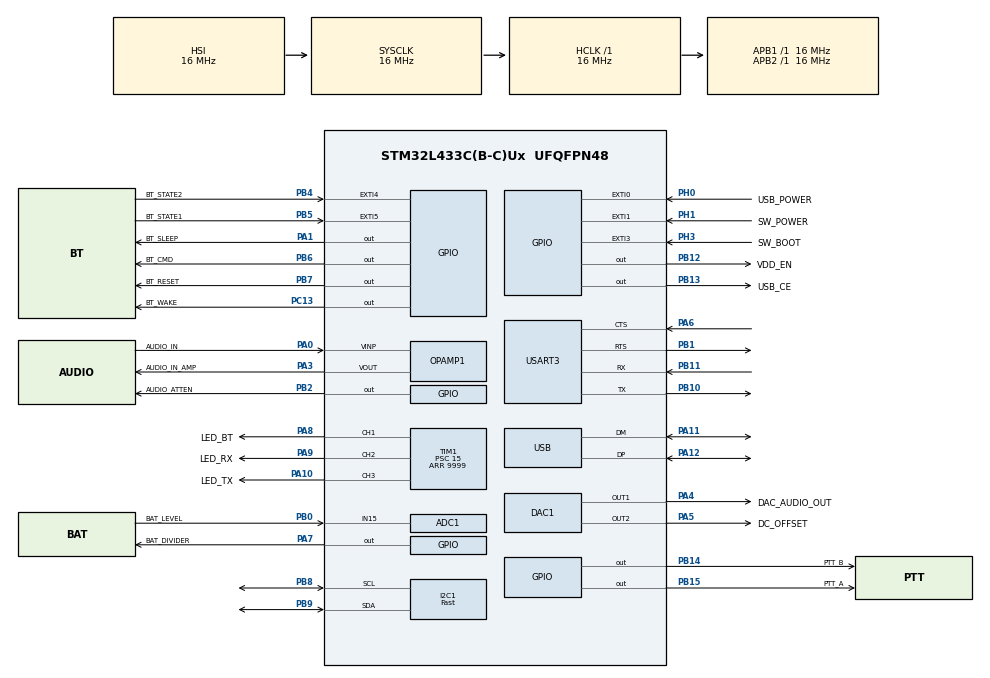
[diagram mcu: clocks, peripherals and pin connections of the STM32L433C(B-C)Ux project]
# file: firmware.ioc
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ADC1.Channel-0\#ChannelRegularConversion=ADC_CHANNEL_8
ADC1.DMAContinuousRequests=ENABLE
ADC1.EOCSelection=ADC_EOC_SEQ_CONV
ADC1.EnableAnalogWatchDog1=false
ADC1.EnableAnalogWatchDog2=false
ADC1.EnableInjectedConversion=ENABLE
ADC1.ExternalTrigConv=ADC_EXTERNALTRIG_T6_TRGO
ADC1.InjNumberOfConversion=0
ADC1.NbrOfConversion=1
ADC1.NbrOfConversionFlag=1
ADC1.OffsetNumber-0\#ChannelRegularConversion=ADC_OFFSET_NONE
ADC1.Overrun=ADC_OVR_DATA_OVERWRITTEN
ADC1.OversamplingMode=ENABLE
ADC1.OversamplingStopReset=ADC_REGOVERSAMPLING_RESUMED_MODE
ADC1.Rank-0\#ChannelRegularConversion=1
ADC1.Ratio=ADC_OVERSAMPLING_RATIO_16
ADC1.RightBitShift=ADC_RIGHTBITSHIFT_2
ADC1.SamplingTime-0\#ChannelRegularConversion=ADC_SAMPLETIME_24CYCLES_5
ADC1.master=1
CRC.CRCLength=CRC_POLYLENGTH_16B
CRC.DefaultInitValueUse=DEFAULT_INIT_VALUE_DISABLE
CRC.DefaultPolynomialUse=DEFAULT_POLYNOMIAL_DISABLE
CRC.GeneratingPolynomial=X12+X5+X0
CRC.InitValue=0xFFFF
CRC.InputDataInversionMode=CRC_INPUTDATA_INVERSION_BYTE
DAC1.DAC_Channel-DAC_OUT2_ExtAndInt=DAC_CHANNEL_2
DAC1.DAC_Trigger-DAC_OUT1_ExtAndInt=DAC_TRIGGER_T7_TRGO
DAC1.DAC_Trigger-DAC_OUT2_ExtAndInt=DAC_TRIGGER_NONE
Dma.ADC1.0.Direction=DMA_PERIPH_TO_MEMORY
Dma.ADC1.0.Instance=DMA1_Channel1
Dma.ADC1.0.MemDataAlignment=DMA_MDATAALIGN_HALFWORD
Dma.ADC1.0.MemInc=DMA_MINC_ENABLE
Dma.ADC1.0.Mode=DMA_CIRCULAR
Dma.ADC1.0.PeriphDataAlignment=DMA_PDATAALIGN_HALFWORD
Dma.ADC1.0.PeriphInc=DMA_PINC_DISABLE
Dma.ADC1.0.Priority=DMA_PRIORITY_LOW
Dma.DAC_CH1.1.Direction=DMA_MEMORY_TO_PERIPH
Dma.DAC_CH1.1.Instance=DMA2_Channel4
Dma.DAC_CH1.1.MemDataAlignment=DMA_MDATAALIGN_HALFWORD
Dma.DAC_CH1.1.MemInc=DMA_MINC_ENABLE
Dma.DAC_CH1.1.Mode=DMA_CIRCULAR
Dma.DAC_CH1.1.PeriphDataAlignment=DMA_PDATAALIGN_HALFWORD
Dma.DAC_CH1.1.PeriphInc=DMA_PINC_DISABLE
Dma.DAC_CH1.1.Priority=DMA_PRIORITY_LOW
Dma.I2C1_RX.5.Direction=DMA_PERIPH_TO_MEMORY
Dma.I2C1_RX.5.Instance=DMA1_Channel7
Dma.I2C1_RX.5.MemDataAlignment=DMA_MDATAALIGN_BYTE
Dma.I2C1_RX.5.MemInc=DMA_MINC_ENABLE
Dma.I2C1_RX.5.Mode=DMA_NORMAL
Dma.I2C1_RX.5.PeriphDataAlignment=DMA_PDATAALIGN_BYTE
Dma.I2C1_RX.5.PeriphInc=DMA_PINC_DISABLE
Dma.I2C1_RX.5.Priority=DMA_PRIORITY_LOW
Dma.I2C1_TX.4.Direction=DMA_MEMORY_TO_PERIPH
Dma.I2C1_TX.4.Instance=DMA1_Channel6
Dma.I2C1_TX.4.MemDataAlignment=DMA_MDATAALIGN_BYTE
Dma.I2C1_TX.4.MemInc=DMA_MINC_ENABLE
Dma.I2C1_TX.4.Mode=DMA_NORMAL
Dma.I2C1_TX.4.PeriphDataAlignment=DMA_PDATAALIGN_BYTE
Dma.I2C1_TX.4.PeriphInc=DMA_PINC_DISABLE
Dma.I2C1_TX.4.Priority=DMA_PRIORITY_LOW
Dma.Request0=ADC1
Dma.Request1=DAC_CH1
Dma.Request2=USART3_TX
Dma.Request3=USART3_RX
Dma.Request4=I2C1_TX
Dma.Request5=I2C1_RX
Dma.USART3_RX.3.Direction=DMA_PERIPH_TO_MEMORY
Dma.USART3_RX.3.Instance=DMA1_Channel3
Dma.USART3_RX.3.MemDataAlignment=DMA_MDATAALIGN_BYTE
Dma.USART3_RX.3.MemInc=DMA_MINC_ENABLE
Dma.USART3_RX.3.Mode=DMA_CIRCULAR
Dma.USART3_RX.3.PeriphDataAlignment=DMA_PDATAALIGN_BYTE
Dma.USART3_RX.3.PeriphInc=DMA_PINC_DISABLE
Dma.USART3_RX.3.Priority=DMA_PRIORITY_LOW
Dma.USART3_TX.2.Direction=DMA_MEMORY_TO_PERIPH
Dma.USART3_TX.2.Instance=DMA1_Channel2
Dma.USART3_TX.2.MemDataAlignment=DMA_MDATAALIGN_BYTE
Dma.USART3_TX.2.MemInc=DMA_MINC_ENABLE
Dma.USART3_TX.2.Mode=DMA_NORMAL
Dma.USART3_TX.2.PeriphDataAlignment=DMA_PDATAALIGN_BYTE
Dma.USART3_TX.2.PeriphInc=DMA_PINC_DISABLE
Dma.USART3_TX.2.Priority=DMA_PRIORITY_LOW
FREERTOS.HEAP_NUMBER=3
FREERTOS.MEMORY_ALLOCATION=2
FREERTOS.Queues01=ioEventQueue,16,uint32_t,0,Static,ioEventQueueBuffer,ioEventQueueControlBlock;audioInputQueue,8,uint8_t,0,Static,audioInputQueueBuffer,audioInputQueueControlBlock;hdlcInputQueue,3,uint32_t,0,Static,hdlcInputQueueBuffer,hdlcInputQueueControlBlock;hdlcOutputQueue,3,uint32_t,0,Static,hdlcOutputQueueBuffer,hdlcOutputQueueControlBlock;dacOutputQueue,128,uint8_t,0,Static,dacOutputQueueBuffer,dacOutputQueueControlBlock;adcInputQueue,3,uint32_t,0,Static,adcInputQueueBuffer,adcInputQueueControlBlock
FREERTOS.Tasks01=ioEventTask,-2,384,startIOEventTask,As weak,NULL,Static,ioEventTaskBuffer,ioEventTaskControlBlock;audioInputTask,1,512,startAudioInputTask,As external,NULL,Static,audioInputTaskBuffer,audioInputTaskControlBlock;modulatorTask,1,384,startModulatorTask,As external,NULL,Static,modulatorTaskBuffer,modulatorTaskControlBlock
FREERTOS.Timers01=usbShutdownTimer,shutdown,osTimerOnce,Default,NULL,Static,usbShutdownTimerControlBlock;powerOffTimer,powerOffTimerCallback,osTimerOnce,Default,NULL,Static,powerOffTimerControlBlock
FREERTOS.configCHECK_FOR_STACK_OVERFLOW=1
FREERTOS.configENABLE_BACKWARD_COMPATIBILITY=0
FREERTOS.configENABLE_FPU=1
FREERTOS.configTOTAL_HEAP_SIZE=2048
FREERTOS.configUSE_APPLICATION_TASK_TAG=0
FREERTOS.configUSE_MALLOC_FAILED_HOOK=1
FREERTOS.configUSE_NEWLIB_REENTRANT=1
FREERTOS.configUSE_TICKLESS_IDLE=0
FREERTOS.configUSE_TIMERS=1
I2C1.I2C_Speed_Mode=I2C_Fast
I2C1.Timing=0x00300617
IWDG.Prescaler=IWDG_PRESCALER_64
Mcu.Family=STM32L4
Mcu.Name=STM32L433C(B-C)Ux
Mcu.Package=UFQFPN48
Mcu.UserConstants=EEPROM_ADDRESS,0xA0;EEPROM_CAPACITY,4096;EEPROM_PAGE_SIZE,32;EEPROM_WRITE_TIME,5
NVIC.ADC1_IRQn=true\:5\:0\:false\:false\:true\:true\:true\:false\:false
NVIC.DMA1_Channel1_IRQn=true\:5\:0\:false\:false\:true\:true\:false\:true\:true
NVIC.DMA1_Channel2_IRQn=true\:5\:0\:false\:false\:true\:true\:false\:true\:true
NVIC.DMA1_Channel3_IRQn=true\:5\:0\:false\:false\:true\:true\:false\:true\:true
NVIC.DMA1_Channel6_IRQn=true\:5\:0\:false\:false\:true\:true\:false\:true\:true
NVIC.DMA1_Channel7_IRQn=true\:5\:0\:false\:false\:true\:true\:false\:true\:true
NVIC.DMA2_Channel4_IRQn=true\:5\:0\:false\:false\:true\:true\:false\:true\:true
NVIC.EXTI0_IRQn=true\:5\:0\:true\:false\:true\:true\:true\:true\:false
NVIC.EXTI1_IRQn=true\:5\:0\:true\:false\:true\:true\:true\:true\:false
NVIC.EXTI3_IRQn=true\:5\:0\:true\:false\:true\:true\:true\:true\:false
NVIC.EXTI4_IRQn=true\:5\:0\:false\:false\:true\:true\:true\:true\:false
NVIC.EXTI9_5_IRQn=true\:5\:0\:false\:false\:true\:true\:true\:true\:false
NVIC.PriorityGroup=NVIC_PRIORITYGROUP_4
NVIC.TIM1_UP_TIM16_IRQn=true\:5\:0\:false\:false\:true\:true\:true\:true\:true
NVIC.TIM2_IRQn=true\:0\:0\:false\:false\:true\:false\:false\:true\:true
NVIC.TimeBase=TIM2_IRQn
NVIC.TimeBaseIP=TIM2
NVIC.USART3_IRQn=true\:5\:0\:false\:false\:true\:true\:true\:true\:true
NVIC.USB_IRQn=true\:5\:0\:false\:false\:true\:true\:false\:true\:true
OPAMP1.PowerSupplyRange=OPAMP_POWERSUPPLY_HIGH
PA0.GPIO_Label=AUDIO_IN
PA0.Mode=PGA Not Connected
PA0.Signal=OPAMP1_VINP
PA1.GPIO_Label=BT_SLEEP
PA1.GPIO_ModeDefaultOutputPP=GPIO_MODE_OUTPUT_PP
PA1.PinState=GPIO_PIN_SET
PA1.Signal=GPIO_Output
PA10.GPIO_Label=LED_TX
PA10.GPIO_ModeDefaultOutputPP=GPIO_MODE_OUTPUT_OD
PA10.GPIO_ModeDefaultPP=GPIO_MODE_AF_OD
PA10.PinState=GPIO_PIN_SET
PA10.Signal=SharedStack_PA10
PA10.Stacked=true
PA11.Mode=Device
PA11.Signal=USB_DM
PA12.Mode=Device
PA12.Signal=USB_DP
PA13\ (JTMS-SWDIO).Mode=Trace_Asynchronous_SW
PA13\ (JTMS-SWDIO).Signal=SYS_JTMS-SWDIO
PA14\ (JTCK-SWCLK).Mode=Trace_Asynchronous_SW
PA14\ (JTCK-SWCLK).Signal=SYS_JTCK-SWCLK
PA2.Mode=Clock-out-LSCO
PA2.Signal=RCC_LSCO
PA3.GPIO_Label=AUDIO_IN_AMP
PA3.Mode=PGA Not Connected
PA3.Signal=OPAMP1_VOUT
PA4.GPIO_Label=DAC_AUDIO_OUT
PA4.Signal=COMP_DAC11_group
PA5.GPIO_Label=DC_OFFSET
PA5.Signal=COMP_DAC12_group
PA6.Mode=CTS_RTS
PA6.Signal=USART3_CTS
PA7.GPIO_Label=BAT_DIVIDER
PA7.GPIO_ModeDefaultOutputPP=GPIO_MODE_OUTPUT_OD
PA7.PinState=GPIO_PIN_SET
PA7.Signal=GPIO_Output
PA8.GPIO_Label=LED_BT
PA8.GPIO_ModeDefaultOutputPP=GPIO_MODE_OUTPUT_OD
PA8.GPIO_ModeDefaultPP=GPIO_MODE_AF_OD
PA8.PinState=GPIO_PIN_SET
PA8.Signal=S_TIM1_CH1
PA8.Stacked=true
PA9.GPIO_Label=LED_RX
PA9.GPIO_ModeDefaultOutputPP=GPIO_MODE_OUTPUT_OD
PA9.GPIO_ModeDefaultPP=GPIO_MODE_AF_OD
PA9.PinState=GPIO_PIN_SET
PA9.Signal=SharedStack_PA9
PA9.Stacked=true
PB0.GPIO_Label=BAT_LEVEL
PB0.Signal=ADCx_IN15
PB1.Mode=CTS_RTS
PB1.Signal=USART3_RTS
PB10.Mode=Asynchronous
PB10.Signal=USART3_TX
PB11.GPIO_PuPd=GPIO_NOPULL
PB11.Mode=Asynchronous
PB11.Signal=USART3_RX
PB12.GPIO_Label=VDD_EN
PB12.PinState=GPIO_PIN_SET
PB12.Signal=GPIO_Output
PB13.GPIO_Label=USB_CE
PB13.GPIO_ModeDefaultOutputPP=GPIO_MODE_OUTPUT_OD
PB13.PinState=GPIO_PIN_SET
PB13.Signal=GPIO_Output
PB14.GPIO_Label=PTT_B
PB14.Signal=GPIO_Output
PB15.GPIO_Label=PTT_A
PB15.Signal=GPIO_Output
PB2.GPIO_Label=AUDIO_ATTEN
PB2.GPIO_ModeDefaultOutputPP=GPIO_MODE_OUTPUT_OD
PB2.PinState=GPIO_PIN_SET
PB2.Signal=GPIO_Output
PB3\ (JTDO-TRACESWO).Mode=Trace_Asynchronous_SW
PB3\ (JTDO-TRACESWO).Signal=SYS_JTDO-SWO
PB4\ (NJTRST).GPIO_Label=BT_STATE2
PB4\ (NJTRST).GPIO_ModeDefaultEXTI=GPIO_MODE_IT_RISING_FALLING
PB4\ (NJTRST).Signal=GPXTI4
PB5.GPIO_Label=BT_STATE1
PB5.GPIO_ModeDefaultEXTI=GPIO_MODE_IT_RISING_FALLING
PB5.Signal=GPXTI5
PB6.GPIO_Label=BT_CMD
PB6.GPIO_ModeDefaultOutputPP=GPIO_MODE_OUTPUT_OD
PB6.PinState=GPIO_PIN_SET
PB6.Signal=GPIO_Output
PB7.GPIO_Label=BT_RESET
PB7.GPIO_ModeDefaultOutputPP=GPIO_MODE_OUTPUT_OD
PB7.PinState=GPIO_PIN_SET
PB7.Signal=GPIO_Output
PB8.GPIO_Pu=GPIO_NOPULL
PB8.Mode=I2C
PB8.Signal=I2C1_SCL
PB9.GPIO_Pu=GPIO_NOPULL
PB9.Mode=I2C
PB9.Signal=I2C1_SDA
PC13.GPIO_Label=BT_WAKE
PC13.GPIO_ModeDefaultOutputPP=GPIO_MODE_OUTPUT_OD
PC13.PinState=GPIO_PIN_RESET
PC13.Signal=GPIO_Output
PC14-OSC32_IN\ (PC14).Mode=LSE-External-Oscillator
PC14-OSC32_IN\ (PC14).Signal=RCC_OSC32_IN
PC15-OSC32_OUT\ (PC15).Mode=LSE-External-Oscillator
PC15-OSC32_OUT\ (PC15).Signal=RCC_OSC32_OUT
PH0-OSC_IN\ (PH0).GPIO_Label=USB_POWER
PH0-OSC_IN\ (PH0).GPIO_ModeDefaultEXTI=GPIO_MODE_IT_RISING_FALLING
PH0-OSC_IN\ (PH0).GPIO_PuPd=GPIO_PULLDOWN
PH0-OSC_IN\ (PH0).Signal=GPXTI0
PH1-OSC_OUT\ (PH1).GPIO_Label=SW_POWER
PH1-OSC_OUT\ (PH1).GPIO_ModeDefaultEXTI=GPIO_MODE_IT_RISING_FALLING
PH1-OSC_OUT\ (PH1).Signal=GPXTI1
PH3-BOOT0.GPIO_Label=SW_BOOT
PH3-BOOT0.GPIO_ModeDefaultEXTI=GPIO_MODE_IT_RISING_FALLING
PH3-BOOT0.Signal=GPXTI3
ProjectManager.HeapSize=0x200
ProjectManager.StackSize=0x400
ProjectManager.TargetToolchain=CMake
RCC.ADCCLockSelection=RCC_ADCCLKSOURCE_SYSCLK
RCC.ADCFreq_Value=16000000
RCC.AHBFreq_Value=16000000
RCC.APB1Freq_Value=16000000
RCC.APB1TimFreq_Value=16000000
RCC.APB2Freq_Value=16000000
RCC.APB2TimFreq_Value=16000000
RCC.CK48CLockSelection=RCC_USBCLKSOURCE_MSI
RCC.CortexFreq_Value=16000000
RCC.HCLKFreq_Value=16000000
RCC.HSE_VALUE=8000000
RCC.HSI48_VALUE=48000000
RCC.HSI_VALUE=16000000
RCC.I2C1CLockSelection=RCC_I2C1CLKSOURCE_HSI
RCC.LSCOSource1=RCC_LSCOSOURCE_LSE
RCC.LSE_Drive_Capability=RCC_LSEDRIVE_MEDIUMLOW
RCC.MSIClockRange=RCC_MSIRANGE_11
RCC.MSI_VALUE=48000000
RCC.PLLM=6
RCC.PLLN=12
RCC.PLLSAI1N=20
RCC.PREFETCH_ENABLE=1
RCC.RCC_MCO1Source=RCC_MCO1SOURCE_MSI
RCC.RTCClockSelection=RCC_RTCCLKSOURCE_LSE
RCC.SYSCLKFreq_VALUE=16000000
RCC.SYSCLKSource=RCC_SYSCLKSOURCE_HSI
RCC.USART3CLockSelection=RCC_USART3CLKSOURCE_HSI
RCC.USBFreq_Value=48000000
RCC.VCOOutputFreq_Value=96000000
SH.ADCx_IN15.0=ADC1_IN15,IN15-Single-Ended
SH.COMP_DAC11_group.0=DAC1_OUT1,DAC_OUT1_ExtAndInt
SH.COMP_DAC12_group.0=DAC1_OUT2,DAC_OUT2_ExtAndInt
SH.S_TIM1_CH1.0=TIM1_CH1,PWM Generation1 CH1
SH.SharedStack_PA10.0=TIM1_CH3,PWM Generation3 CH3
SH.SharedStack_PA9.0=TIM1_CH2,PWM Generation2 CH2
STMicroelectronics.X-CUBE-ALGOBUILD.1.3.0.LibraryCcDSPOoLibraryJjDSPOoLibrary=true
TIM1.Channel-PWM\ Generation1\ CH1=TIM_CHANNEL_1
TIM1.Channel-PWM\ Generation2\ CH2=TIM_CHANNEL_2
TIM1.Channel-PWM\ Generation3\ CH3=TIM_CHANNEL_3
TIM1.OCIdleState_1=TIM_OCIDLESTATE_SET
TIM1.OCIdleState_2=TIM_OCIDLESTATE_SET
TIM1.OCIdleState_3=TIM_OCIDLESTATE_SET
TIM1.OCPolarity_1=TIM_OCPOLARITY_LOW
TIM1.OCPolarity_2=TIM_OCPOLARITY_LOW
TIM1.OCPolarity_3=TIM_OCPOLARITY_LOW
TIM1.Period=9999
TIM1.Prescaler=15
TIM6.AutoReloadPreload=TIM_AUTORELOAD_PRELOAD_ENABLE
TIM6.Period=1817
TIM6.TIM_MasterOutputTrigger=TIM_TRGO_UPDATE
TIM7.AutoReloadPreload=TIM_AUTORELOAD_PRELOAD_ENABLE
TIM7.Period=1817
TIM7.TIM_MasterOutputTrigger=TIM_TRGO_UPDATE
USART3.VirtualMode-Asynchronous=VM_ASYNC
USB.battery_charging_enable=ENABLE
USB.lpm_enable=DISABLE
USB_DEVICE.APP_RX_DATA_SIZE=64
USB_DEVICE.APP_TX_DATA_SIZE=64
USB_DEVICE.CLASS_NAME_FS=CDC
USB_DEVICE.MANUFACTURER_STRING=Mobilinkd LLC
USB_DEVICE.PRODUCT_STRING_CDC_FS=Mobilinkd TNC3 v2.1.1
USB_DEVICE.USBD_LPM_ENABLED=1
USB_DEVICE.USBD_MAX_NUM_CONFIGURATION=2
USB_DEVICE.USBD_SELF_POWERED=1
USB_DEVICE.VirtualMode=Cdc
USB_DEVICE.VirtualModeFS=Cdc_FS
VP_ADC1_OPAMP1_OUT.Mode=IN8-OPAMP1-Single-Ended
VP_ADC1_Vref_Input.Mode=IN-Vrefint
VP_CRC_VS_CRC.Mode=CRC_Activate
VP_FREERTOS_VS_CMSIS_V1.Mode=CMSIS_V1
VP_IWDG_VS_IWDG.Mode=IWDG_Activate
VP_RCC_LSE.Mode=CRS SYNC Source LSE
VP_RNG_VS_RNG.Mode=RNG_Activate
VP_RTC_VS_RTC_Activate.Mode=RTC_Enabled
VP_RTC_VS_RTC_Calendar.Mode=RTC_Calendar
VP_STMicroelectronics.X-CUBE-ALGOBUILD_VS_DSPOoLibraryJjLibrary_1.3.0_1.3.0.Mode=DSPOoLibraryJjLibrary
VP_SYS_VS_tim2.Mode=TIM2
VP_SYS_V_PVD_IN.Mode=Mode_PVD_Int
VP_TIM1_VS_ClockSourceINT.Mode=Internal
VP_TIM6_VS_ClockSourceINT.Mode=Enable_Timer
VP_TIM7_VS_ClockSourceINT.Mode=Enable_Timer
VP_USB_DEVICE_VS_USB_DEVICE_CDC_FS.Mode=CDC_FS
board=custom

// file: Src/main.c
/* USER CODE BEGIN Header */
/**
  ******************************************************************************
  * @file           : main.c
  * @brief          : Main program body
  ******************************************************************************
  * @attention
  *
  * Copyright (c) 2024 STMicroelectronics.
  * All rights reserved.
  *
  * This software is licensed under terms that can be found in the LICENSE file
  * in the root directory of this software component.
  * If no LICENSE file comes with this software, it is provided AS-IS.
  *
  ******************************************************************************
  */
/* USER CODE END Header */
#include "main.h"
#include "cmsis_os.h"

/* USER CODE BEGIN Includes */
#include "usbd_core.h"
#include "IOEventTask.h"
#include "PortInterface.h"
#include "LEDIndicator.h"
#include "bm78.h"
#include "KissHardware.h"
#include "Log.h"
#include "power.h"

/* USER CODE END Includes */

ADC_HandleTypeDef hadc1;
DMA_HandleTypeDef hdma_adc1;

CRC_HandleTypeDef hcrc;

DAC_HandleTypeDef hdac1;
DMA_HandleTypeDef hdma_dac_ch1;

I2C_HandleTypeDef hi2c1;
DMA_HandleTypeDef hdma_i2c1_tx;
DMA_HandleTypeDef hdma_i2c1_rx;

IWDG_HandleTypeDef hiwdg;

OPAMP_HandleTypeDef hopamp1;

RNG_HandleTypeDef hrng;

RTC_HandleTypeDef hrtc;

TIM_HandleTypeDef htim1;
TIM_HandleTypeDef htim6;
TIM_HandleTypeDef htim7;

UART_HandleTypeDef huart3;
DMA_HandleTypeDef hdma_usart3_tx;
DMA_HandleTypeDef hdma_usart3_rx;

osThreadId ioEventTaskHandle;
uint32_t ioEventTaskBuffer[ 384 ];
osStaticThreadDef_t ioEventTaskControlBlock;
osThreadId audioInputTaskHandle;
uint32_t audioInputTaskBuffer[ 512 ];
osStaticThreadDef_t audioInputTaskControlBlock;
osThreadId modulatorTaskHandle;
uint32_t modulatorTaskBuffer[ 384 ];
osStaticThreadDef_t modulatorTaskControlBlock;
osMessageQId ioEventQueueHandle;
uint8_t ioEventQueueBuffer[ 16 * sizeof( uint32_t ) ];
osStaticMessageQDef_t ioEventQueueControlBlock;
osMessageQId audioInputQueueHandle;
uint8_t audioInputQueueBuffer[ 8 * sizeof( uint8_t ) ];
osStaticMessageQDef_t audioInputQueueControlBlock;
osMessageQId hdlcInputQueueHandle;
uint8_t hdlcInputQueueBuffer[ 3 * sizeof( uint32_t ) ];
osStaticMessageQDef_t hdlcInputQueueControlBlock;
osMessageQId hdlcOutputQueueHandle;
uint8_t hdlcOutputQueueBuffer[ 3 * sizeof( uint32_t ) ];
osStaticMessageQDef_t hdlcOutputQueueControlBlock;
osMessageQId dacOutputQueueHandle;
uint8_t dacOutputQueueBuffer[ 128 * sizeof( uint8_t ) ];
osStaticMessageQDef_t dacOutputQueueControlBlock;
osMessageQId adcInputQueueHandle;
uint8_t adcInputQueueBuffer[ 3 * sizeof( uint32_t ) ];
osStaticMessageQDef_t adcInputQueueControlBlock;
osTimerId usbShutdownTimerHandle;
osStaticTimerDef_t usbShutdownTimerControlBlock;
osTimerId powerOffTimerHandle;
osStaticTimerDef_t powerOffTimerControlBlock;
/* USER CODE BEGIN PV */
/* Private variables ---------------------------------------------------------*/

int lost_power = 0;
int reset_requested = 0;
char serial_number_64[24] = {0};
// Make sure it is not overwritten during resets (bss3).
uint8_t mac_address[6] __attribute__((section(".bss3"))) = {0};
char error_message[80] __attribute__((section(".bss3"))) = {0};
// USB power control -- need to renegotiate USB charging in STOP mode.
int go_back_to_sleep __attribute__((section(".bss3")));
int charging_enabled __attribute__((section(".bss3")));
int usb_wake_state __attribute__((section(".bss3")));
int reset_button = 0;

uint16_t mobilinkd_model;
uint16_t mobilinkd_date_code;
uint32_t mobilinkd_serial_number;

/* USER CODE END PV */

void SystemClock_Config(void);
static void MX_GPIO_Init(void);
static void MX_DMA_Init(void);
void startIOEventTask(void const * argument);
extern void startAudioInputTask(void const * argument);
extern void startModulatorTask(void const * argument);
void shutdown(void const * argument);
void powerOffTimerCallback(void const * argument);

/* USER CODE BEGIN PFP */
/* Private function prototypes -----------------------------------------------*/

/* USER CODE END PFP */

/* USER CODE BEGIN 0 */

/*
 * Same algorithm as here: https://github.com/libopencm3/libopencm3/blob/master/lib/stm32/desig.c
 */
void encode_serial_number()
{
    uint8_t *uid = (uint8_t *)UID_BASE;

    uint8_t serial[6];
    serial[0] = uid[11];
    serial[1] = uid[10] + uid[2];
    serial[2] = uid[9];
    serial[3] = uid[8] + uid[0];
    serial[4] = uid[7];
    serial[5] = uid[6];

    snprintf(
        serial_number_64,
        sizeof(serial_number_64),
        "%02X%02X%02X%02X%02X%02X (%04lu)",
        serial[0], serial[1], serial[2],
        serial[3], serial[4], serial[5],
        mobilinkd_serial_number
    );
}

static ResetCause getResetCause()
{
  uint32_t wakeEvent = PWR->SR1 & 0x1F; // Wake-up event.

  // Capture cause of reset/wake-up.
  ResetCause resetCause = RESET_CAUSE_UNKNOWN;
  if (RCC->CSR & RCC_CSR_SFTRSTF) {
      resetCause = RESET_CAUSE_SOFT;
  } else if (RCC->CSR & RCC_CSR_IWDGRSTF) {
      resetCause = RESET_CAUSE_IWDG;
  } else if (RCC->CSR & RCC_CSR_PINRSTF) {
      resetCause = RESET_CAUSE_HARD;
      reset_button = 1;
  } else if (RCC->CSR & RCC_CSR_BORRSTF) {
      resetCause = RESET_CAUSE_BOR;
  } else if (wakeEvent) {
      resetCause = RESET_CAUSE_WUF;
  } else if (__HAL_RTC_WAKEUPTIMER_GET_FLAG(&hrtc, RTC_FLAG_WUTF) != RESET) {
      resetCause = RESET_CAUSE_WUTF;
  }
  __HAL_RCC_CLEAR_RESET_FLAGS();

  return resetCause;
}

/* USER CODE END 0 */

int main(void)
{

  /* USER CODE BEGIN 1 */
  __HAL_DBGMCU_FREEZE_IWDG();

  // Capture cause of reset/wake-up.
  ResetCause resetCause = getResetCause();

  // Read serial, model, date from OTP record. Values are big-endian.
  mobilinkd_serial_number = __builtin_bswap32(*(uint32_t*) (0x1FFF7000));
  mobilinkd_model = __builtin_bswap16(*(uint16_t*) (0x1FFF7004));
  mobilinkd_date_code = __builtin_bswap16(*(uint16_t*) (0x1FFF7006));

  if (mobilinkd_serial_number == 0xFFFFFFFF) mobilinkd_serial_number = 0;

  /* USER CODE END 1 */

  /* MCU Configuration--------------------------------------------------------*/

  /* Reset of all peripherals, Initializes the Flash interface and the Systick. */
  HAL_Init();

  /* Configure the system clock */
  SystemClock_Config();

  /* USER CODE BEGIN SysInit */
  // SysClock starts at 16MHz and we want a 2MHz SWO.
  TPI->ACPR = 7;

  // Note that it is important that all GPIO interrupts are disabled until
  // the FreeRTOS kernel has started.  All GPIO interrupts send messages
  // to the ioEventTask thread.  Attempts to use any message queues before
  // FreeRTOS has started will lead to problems.  Because of this, GPIO
  // interrupts are not enabled until the ioEventTask thread starts.

  /* USER CODE END SysInit */

  /* Initialize all configured peripherals */
  MX_GPIO_Init();
  MX_DMA_Init();
  MX_RTC_Init();
  MX_TIM1_Init();
  /* USER CODE BEGIN 2 */

  GPIO_PinState power_switch_state = !!(SW_POWER_GPIO_Port->IDR & SW_POWER_Pin);
  // Log the cause of the reset.
  switch (resetCause) {
  case RESET_CAUSE_SOFT:
    INFO("software reset");
    break;
  case RESET_CAUSE_IWDG:
    INFO("watchdog reset");
    // Reset the BKUP_TNC_LOWPOWER_STATE register to ensure the TNC wakes
    // after a watchdog reset.
    HAL_PWR_EnableBkUpAccess();
    WRITE_REG(BKUP_TNC_LOWPOWER_STATE, 0x0);
    HAL_PWR_DisableBkUpAccess();
    break;
  case RESET_CAUSE_HARD:
    INFO("hardware reset");
    // Reset the BKUP_TNC_LOWPOWER_STATE register to ensure the TNC wakes
    // after a hardware reset.
    HAL_PWR_EnableBkUpAccess();
    WRITE_REG(BKUP_TNC_LOWPOWER_STATE, 0x0);
    HAL_PWR_DisableBkUpAccess();
    break;
  case RESET_CAUSE_BOR:
    INFO("brown-out reset");
    // Reset the BKUP_TNC_LOWPOWER_STATE register to ensure the TNC wakes
    // after a brown-out reset.
    HAL_PWR_EnableBkUpAccess();
    WRITE_REG(BKUP_TNC_LOWPOWER_STATE, 0x0);
    HAL_PWR_DisableBkUpAccess();
    break;
  case RESET_CAUSE_WUF:
    INFO("wake-up event: %02lx", PWR->SR1 & 0x1F);
    break;
  case RESET_CAUSE_WUTF:
    INFO("wake-up timer");
    break;
  default:
    INFO("unknown reset, RCC->CSR=0x%08lx", RCC->CSR);
    INFO("unknown reset, RTC->SR=0x%08lx", RTC->ISR);
    INFO("unknown reset, PWR->SR1=0x%08lx", PWR->SR1);
  }
  INFO("PWR->SCR=0x%08lx", PWR->SCR);
  INFO("PWR->CR1=0x%08lx", PWR->CR1);
  __HAL_RCC_CLEAR_RESET_FLAGS();
  uint32_t shutdown_reg = READ_REG(BKUP_TNC_LOWPOWER_STATE);
  // Reset the BKUP_TNC_LOWPOWER_STATE register.
  HAL_PWR_EnableBkUpAccess();
  WRITE_REG(BKUP_TNC_LOWPOWER_STATE, 0x0);
  HAL_PWR_DisableBkUpAccess();

  if (shutdown_reg & TNC_LOWPOWER_DFU) {
    // DFU leaves the system in a bad state. This starts clean.
    HAL_NVIC_SystemReset();
  }

  // TNC_LOWPOWER_RECONFIG is used to negotiate USB power when the device
  // is connected to USB while in a low-power state.
  go_back_to_sleep = !!(shutdown_reg & TNC_LOWPOWER_RECONFIG); // Need to return to sleep.
  // If shutdown because battery is low and there is no VUSB, shutdown again.
  if ((shutdown_reg & TNC_LOWPOWER_LOW_BAT) && !(USB_POWER_GPIO_Port->IDR & USB_POWER_Pin)) {
    HAL_PWR_EnableBkUpAccess();
    WRITE_REG(BKUP_TNC_LOWPOWER_STATE, TNC_LOWPOWER_LOW_BAT);
    HAL_PWR_DisableBkUpAccess();
    WARN("Battery too low to start");
    indicate_battery_low();
    HAL_Delay(3000);
    go_back_to_sleep = 1;
  }

  INFO("start");
  if ((resetCause == RESET_CAUSE_SOFT || resetCause == RESET_CAUSE_IWDG) && error_message[0] != 0) {
    error_message[79] = 0;
    WARN(error_message);
  }
  error_message[0] = 0;
  if (shutdown_reg == 0) {
    memset(mac_address, 0, 6);
    memset(error_message, 0, 80);
    charging_enabled = 0;
    usb_wake_state = 0;
  }

  // Needed to check battery level.
  enable_vdd();
  HAL_Delay(10);
  MX_ADC1_Init();
  MX_TIM6_Init();
  if (HAL_ADCEx_Calibration_Start(&BATTERY_ADC_HANDLE, ADC_SINGLE_ENDED) != HAL_OK) {
    Error_Handler();
  }

  // Don't start up at all if battery is low.
  if (!go_back_to_sleep && is_battery_low()) {
    WARN("low battery");
    indicate_battery_low();
    HAL_PWR_EnableBkUpAccess();
    WRITE_REG(BKUP_TNC_LOWPOWER_STATE, TNC_LOWPOWER_LOW_BAT);
    HAL_PWR_DisableBkUpAccess();
    HAL_Delay(3000);
    go_back_to_sleep = 1;
  }

  SCB->SHCSR |= 0x70000;    // Enable fault handlers;
  if (!go_back_to_sleep) {
      indicate_turning_on();    // LEDs on during boot.
      if (power_switch_state && reset_button) {
        reset_requested = 1;
      }
  }

  encode_serial_number();

  MX_DAC1_Init();
  MX_OPAMP1_Init();
  MX_TIM7_Init();
  MX_CRC_Init();
  MX_RNG_Init();
  MX_I2C1_Init();
  MX_USART3_UART_Init();
  MX_IWDG_Init();

  if (!go_back_to_sleep) {
      HAL_GPIO_WritePin(BT_SLEEP_GPIO_Port, BT_SLEEP_Pin, GPIO_PIN_SET); // BT module on.
      HAL_GPIO_WritePin(BT_RESET_GPIO_Port, BT_RESET_Pin, GPIO_PIN_RESET); // BT module out of reset.
      HAL_Delay(1);
      HAL_GPIO_WritePin(BT_RESET_GPIO_Port, BT_RESET_Pin, GPIO_PIN_SET); // BT module out of reset.
      bm78_wait_until_ready();

      // Initialize the BM78 Bluetooth module the first time we boot.
      if (!bm78_initialized() || reset_requested) {
          bm78_initialize();
      } else if (reset_button) {
          bm78_initialize_mac_address();
      }

      HAL_IWDG_Refresh(&hiwdg);

    // Initialize the DC offset DAC and the PGA op amp.  Calibrate the ADC.
    if (HAL_DAC_SetValue(&hdac1, DAC_CHANNEL_2, DAC_ALIGN_12B_R, 2048) != HAL_OK) Error_Handler();
    if (HAL_DAC_Start(&hdac1, DAC_CHANNEL_2) != HAL_OK) Error_Handler();
    if (HAL_OPAMP_SelfCalibrate(&hopamp1) != HAL_OK) Error_Handler();
    if (HAL_OPAMP_Start(&hopamp1) != HAL_OK) Error_Handler();
  }

  // Initialize option bytes.
  FLASH_OBProgramInitTypeDef obInit = {0};
  HAL_FLASHEx_OBGetConfig(&obInit);

  if ((obInit.OptionType & OPTIONBYTE_USER) == RESET) {
    printf("FAIL: option byte init\r\n");
    Error_Handler();
  }

#if 1
  // Do not erase SRAM2 during reset.
  if ((obInit.USERConfig & FLASH_OPTR_SRAM2_RST) == RESET) {
    obInit.OptionType = OPTIONBYTE_USER;
    obInit.USERType = OB_USER_SRAM2_RST;
    obInit.USERConfig = FLASH_OPTR_SRAM2_RST;
    HAL_FLASH_OB_Unlock();
    HAL_FLASHEx_OBProgram(&obInit);
    HAL_FLASH_OB_Lock();
    HAL_FLASH_OB_Launch();
  }
#endif

#if 1
  // Enable hardware parity check on SRAM2
  if ((obInit.USERConfig & FLASH_OPTR_SRAM2_PE) == RESET) {
    obInit.OptionType = OPTIONBYTE_USER;
    obInit.USERType = OB_USER_SRAM2_PE;
    obInit.USERConfig = FLASH_OPTR_SRAM2_PE;
    HAL_FLASH_OB_Unlock();
    HAL_FLASHEx_OBProgram(&obInit);
    HAL_FLASH_OB_Lock();
    HAL_FLASH_OB_Launch();
  }
#endif

  // Disable IWDG in stop2
  HAL_FLASHEx_OBGetConfig(&obInit);
  if ((obInit.USERConfig & FLASH_OPTR_IWDG_STOP)) {
      obInit.OptionType = OPTIONBYTE_USER;
      obInit.USERType = OB_USER_IWDG_STOP;
      obInit.USERConfig = OB_IWDG_STOP_FREEZE;
      HAL_FLASH_Unlock();
      HAL_FLASH_OB_Unlock();
      HAL_FLASHEx_OBProgram(&obInit);
      HAL_FLASH_OB_Launch();
      HAL_FLASH_OB_Lock();
      HAL_FLASH_Lock();
  }

  /* USER CODE END 2 */

  /* USER CODE BEGIN RTOS_SEMAPHORES */
  /* add semaphores, ... */
#pragma GCC diagnostic push
#pragma GCC diagnostic ignored "-Wwrite-strings"    // cmsis-os is not const-correct.
  /* USER CODE END RTOS_SEMAPHORES */

  /* Create the timer(s) */
  /* definition and creation of usbShutdownTimer */
  osTimerStaticDef(usbShutdownTimer, shutdown, &usbShutdownTimerControlBlock);
  usbShutdownTimerHandle = osTimerCreate(osTimer(usbShutdownTimer), osTimerOnce, NULL);

  /* definition and creation of powerOffTimer */
  osTimerStaticDef(powerOffTimer, powerOffTimerCallback, &powerOffTimerControlBlock);
  powerOffTimerHandle = osTimerCreate(osTimer(powerOffTimer), osTimerOnce, NULL);

  /* Create the queue(s) */
  /* definition and creation of ioEventQueue */
  osMessageQStaticDef(ioEventQueue, 16, uint32_t, ioEventQueueBuffer, &ioEventQueueControlBlock);
  ioEventQueueHandle = osMessageCreate(osMessageQ(ioEventQueue), NULL);

  /* definition and creation of audioInputQueue */
  osMessageQStaticDef(audioInputQueue, 8, uint8_t, audioInputQueueBuffer, &audioInputQueueControlBlock);
  audioInputQueueHandle = osMessageCreate(osMessageQ(audioInputQueue), NULL);

  /* definition and creation of hdlcInputQueue */
  osMessageQStaticDef(hdlcInputQueue, 3, uint32_t, hdlcInputQueueBuffer, &hdlcInputQueueControlBlock);
  hdlcInputQueueHandle = osMessageCreate(osMessageQ(hdlcInputQueue), NULL);

  /* definition and creation of hdlcOutputQueue */
  osMessageQStaticDef(hdlcOutputQueue, 3, uint32_t, hdlcOutputQueueBuffer, &hdlcOutputQueueControlBlock);
  hdlcOutputQueueHandle = osMessageCreate(osMessageQ(hdlcOutputQueue), NULL);

  /* definition and creation of dacOutputQueue */
  osMessageQStaticDef(dacOutputQueue, 128, uint8_t, dacOutputQueueBuffer, &dacOutputQueueControlBlock);
  dacOutputQueueHandle = osMessageCreate(osMessageQ(dacOutputQueue), NULL);

  /* definition and creation of adcInputQueue */
  osMessageQStaticDef(adcInputQueue, 3, uint32_t, adcInputQueueBuffer, &adcInputQueueControlBlock);
  adcInputQueueHandle = osMessageCreate(osMessageQ(adcInputQueue), NULL);

  /* USER CODE BEGIN RTOS_QUEUES */
  /* add queues, ... */

//  MX_IWDG_Init();

  /* USER CODE END RTOS_QUEUES */

  /* Create the thread(s) */
  /* definition and creation of ioEventTask */
  osThreadStaticDef(ioEventTask, startIOEventTask, osPriorityLow, 0, 384, ioEventTaskBuffer, &ioEventTaskControlBlock);
  ioEventTaskHandle = osThreadCreate(osThread(ioEventTask), NULL);

  /* definition and creation of audioInputTask */
  osThreadStaticDef(audioInputTask, startAudioInputTask, osPriorityAboveNormal, 0, 512, audioInputTaskBuffer, &audioInputTaskControlBlock);
  audioInputTaskHandle = osThreadCreate(osThread(audioInputTask), NULL);

  /* definition and creation of modulatorTask */
  osThreadStaticDef(modulatorTask, startModulatorTask, osPriorityAboveNormal, 0, 384, modulatorTaskBuffer, &modulatorTaskControlBlock);
  modulatorTaskHandle = osThreadCreate(osThread(modulatorTask), NULL);

  /* USER CODE BEGIN RTOS_THREADS */
  /* add threads, ... */
#pragma GCC diagnostic pop

  osThreadSuspend(audioInputTaskHandle);
  osThreadSuspend(modulatorTaskHandle);

  /* USER CODE END RTOS_THREADS */

  /* Start scheduler */
  osKernelStart();

  /* We should never get here as control is now taken by the scheduler */

  /* Infinite loop */
  while (1)
  {

  }
}

void SystemClock_Config(void)
{
  RCC_OscInitTypeDef RCC_OscInitStruct = {0};
  RCC_ClkInitTypeDef RCC_ClkInitStruct = {0};
  RCC_CRSInitTypeDef RCC_CRSInitStruct = {0};

  /** Configure the main internal regulator output voltage
  */
  if (HAL_PWREx_ControlVoltageScaling(PWR_REGULATOR_VOLTAGE_SCALE1) != HAL_OK)
  {
    Error_Handler();
  }

  /** Configure LSE Drive Capability
  */
  HAL_PWR_EnableBkUpAccess();
  __HAL_RCC_LSEDRIVE_CONFIG(RCC_LSEDRIVE_MEDIUMLOW);

  /** Initializes the RCC Oscillators according to the specified parameters
  * in the RCC_OscInitTypeDef structure.
  */
  RCC_OscInitStruct.OscillatorType = RCC_OSCILLATORTYPE_HSI|RCC_OSCILLATORTYPE_LSI
                              |RCC_OSCILLATORTYPE_LSE|RCC_OSCILLATORTYPE_MSI;
  RCC_OscInitStruct.LSEState = RCC_LSE_ON;
  RCC_OscInitStruct.HSIState = RCC_HSI_ON;
  RCC_OscInitStruct.HSICalibrationValue = RCC_HSICALIBRATION_DEFAULT;
  RCC_OscInitStruct.LSIState = RCC_LSI_ON;
  RCC_OscInitStruct.MSIState = RCC_MSI_ON;
  RCC_OscInitStruct.MSICalibrationValue = 0;
  RCC_OscInitStruct.MSIClockRange = RCC_MSIRANGE_11;
  RCC_OscInitStruct.PLL.PLLState = RCC_PLL_NONE;
  if (HAL_RCC_OscConfig(&RCC_OscInitStruct) != HAL_OK)
  {
    Error_Handler();
  }

  /** Initializes the CPU, AHB and APB buses clocks
  */
  RCC_ClkInitStruct.ClockType = RCC_CLOCKTYPE_HCLK|RCC_CLOCKTYPE_SYSCLK
                              |RCC_CLOCKTYPE_PCLK1|RCC_CLOCKTYPE_PCLK2;
  RCC_ClkInitStruct.SYSCLKSource = RCC_SYSCLKSOURCE_HSI;
  RCC_ClkInitStruct.AHBCLKDivider = RCC_SYSCLK_DIV1;
  RCC_ClkInitStruct.APB1CLKDivider = RCC_HCLK_DIV1;
  RCC_ClkInitStruct.APB2CLKDivider = RCC_HCLK_DIV1;

  if (HAL_RCC_ClockConfig(&RCC_ClkInitStruct, FLASH_LATENCY_0) != HAL_OK)
  {
    Error_Handler();
  }
  HAL_RCCEx_EnableLSCO(RCC_LSCOSOURCE_LSE);

  /** Enable MSI Auto calibration
  */
  HAL_RCCEx_EnableMSIPLLMode();

  /** Enable the SYSCFG APB clock
  */
  __HAL_RCC_CRS_CLK_ENABLE();

  /** Configures CRS
  */
  RCC_CRSInitStruct.Prescaler = RCC_CRS_SYNC_DIV1;
  RCC_CRSInitStruct.Source = RCC_CRS_SYNC_SOURCE_LSE;
  RCC_CRSInitStruct.Polarity = RCC_CRS_SYNC_POLARITY_RISING;
  RCC_CRSInitStruct.ReloadValue = __HAL_RCC_CRS_RELOADVALUE_CALCULATE(48000000,32768);
  RCC_CRSInitStruct.ErrorLimitValue = 34;
  RCC_CRSInitStruct.HSI48CalibrationValue = 32;

  HAL_RCCEx_CRSConfig(&RCC_CRSInitStruct);
}

void MX_ADC1_Init(void)
{

  ADC_ChannelConfTypeDef sConfig = {0};

  /** Common config
  */
  hadc1.Instance = ADC1;
  hadc1.Init.ClockPrescaler = ADC_CLOCK_ASYNC_DIV1;
  hadc1.Init.Resolution = ADC_RESOLUTION_12B;
  hadc1.Init.DataAlign = ADC_DATAALIGN_RIGHT;
  hadc1.Init.ScanConvMode = ADC_SCAN_DISABLE;
  hadc1.Init.EOCSelection = ADC_EOC_SEQ_CONV;
  hadc1.Init.LowPowerAutoWait = DISABLE;
  hadc1.Init.ContinuousConvMode = DISABLE;
  hadc1.Init.NbrOfConversion = 1;
  hadc1.Init.DiscontinuousConvMode = DISABLE;
  hadc1.Init.ExternalTrigConv = ADC_EXTERNALTRIG_T6_TRGO;
  hadc1.Init.ExternalTrigConvEdge = ADC_EXTERNALTRIGCONVEDGE_RISING;
  hadc1.Init.DMAContinuousRequests = ENABLE;
  hadc1.Init.Overrun = ADC_OVR_DATA_OVERWRITTEN;
  hadc1.Init.OversamplingMode = ENABLE;
  hadc1.Init.Oversampling.Ratio = ADC_OVERSAMPLING_RATIO_16;
  hadc1.Init.Oversampling.RightBitShift = ADC_RIGHTBITSHIFT_2;
  hadc1.Init.Oversampling.TriggeredMode = ADC_TRIGGEREDMODE_SINGLE_TRIGGER;
  hadc1.Init.Oversampling.OversamplingStopReset = ADC_REGOVERSAMPLING_RESUMED_MODE;
  if (HAL_ADC_Init(&hadc1) != HAL_OK)
  {
    Error_Handler();
  }

  /** Configure Regular Channel
  */
  sConfig.Channel = ADC_CHANNEL_8;
  sConfig.Rank = ADC_REGULAR_RANK_1;
  sConfig.SamplingTime = ADC_SAMPLETIME_24CYCLES_5;
  sConfig.SingleDiff = ADC_SINGLE_ENDED;
  sConfig.OffsetNumber = ADC_OFFSET_NONE;
  sConfig.Offset = 0;
  if (HAL_ADC_ConfigChannel(&hadc1, &sConfig) != HAL_OK)
  {
    Error_Handler();
  }

}

void MX_CRC_Init(void)
{

  hcrc.Instance = CRC;
  hcrc.Init.DefaultPolynomialUse = DEFAULT_POLYNOMIAL_DISABLE;
  hcrc.Init.DefaultInitValueUse = DEFAULT_INIT_VALUE_DISABLE;
  hcrc.Init.GeneratingPolynomial = 4129;
  hcrc.Init.CRCLength = CRC_POLYLENGTH_16B;
  hcrc.Init.InitValue = 0xFFFF;
  hcrc.Init.InputDataInversionMode = CRC_INPUTDATA_INVERSION_BYTE;
  hcrc.Init.OutputDataInversionMode = CRC_OUTPUTDATA_INVERSION_DISABLE;
  hcrc.InputDataFormat = CRC_INPUTDATA_FORMAT_BYTES;
  if (HAL_CRC_Init(&hcrc) != HAL_OK)
  {
    Error_Handler();
  }

}

void MX_DAC1_Init(void)
{

  DAC_ChannelConfTypeDef sConfig = {0};

  /** DAC Initialization
  */
  hdac1.Instance = DAC1;
  if (HAL_DAC_Init(&hdac1) != HAL_OK)
  {
    Error_Handler();
  }

  /** DAC channel OUT1 config
  */
  sConfig.DAC_SampleAndHold = DAC_SAMPLEANDHOLD_DISABLE;
  sConfig.DAC_Trigger = DAC_TRIGGER_T7_TRGO;
  sConfig.DAC_OutputBuffer = DAC_OUTPUTBUFFER_ENABLE;
  sConfig.DAC_ConnectOnChipPeripheral = DAC_CHIPCONNECT_ENABLE;
  sConfig.DAC_UserTrimming = DAC_TRIMMING_FACTORY;
  if (HAL_DAC_ConfigChannel(&hdac1, &sConfig, DAC_CHANNEL_1) != HAL_OK)
  {
    Error_Handler();
  }

  /** DAC channel OUT2 config
  */
  sConfig.DAC_Trigger = DAC_TRIGGER_NONE;
  if (HAL_DAC_ConfigChannel(&hdac1, &sConfig, DAC_CHANNEL_2) != HAL_OK)
  {
    Error_Handler();
  }

}

void MX_I2C1_Init(void)
{

  hi2c1.Instance = I2C1;
  hi2c1.Init.Timing = 0x00300617;
  hi2c1.Init.OwnAddress1 = 0;
  hi2c1.Init.AddressingMode = I2C_ADDRESSINGMODE_7BIT;
  hi2c1.Init.DualAddressMode = I2C_DUALADDRESS_DISABLE;
  hi2c1.Init.OwnAddress2 = 0;
  hi2c1.Init.OwnAddress2Masks = I2C_OA2_NOMASK;
  hi2c1.Init.GeneralCallMode = I2C_GENERALCALL_DISABLE;
  hi2c1.Init.NoStretchMode = I2C_NOSTRETCH_DISABLE;
  if (HAL_I2C_Init(&hi2c1) != HAL_OK)
  {
    Error_Handler();
  }

  /** Configure Analogue filter
  */
  if (HAL_I2CEx_ConfigAnalogFilter(&hi2c1, I2C_ANALOGFILTER_ENABLE) != HAL_OK)
  {
    Error_Handler();
  }

  /** Configure Digital filter
  */
  if (HAL_I2CEx_ConfigDigitalFilter(&hi2c1, 0) != HAL_OK)
  {
    Error_Handler();
  }

}

void MX_IWDG_Init(void)
{

  hiwdg.Instance = IWDG;
  hiwdg.Init.Prescaler = IWDG_PRESCALER_64;
  hiwdg.Init.Window = 4095;
  hiwdg.Init.Reload = 4095;
  if (HAL_IWDG_Init(&hiwdg) != HAL_OK)
  {
    Error_Handler();
  }

}

void MX_OPAMP1_Init(void)
{

  hopamp1.Instance = OPAMP1;
  hopamp1.Init.PowerSupplyRange = OPAMP_POWERSUPPLY_HIGH;
  hopamp1.Init.Mode = OPAMP_PGA_MODE;
  hopamp1.Init.NonInvertingInput = OPAMP_NONINVERTINGINPUT_IO0;
  hopamp1.Init.InvertingInput = OPAMP_INVERTINGINPUT_CONNECT_NO;
  hopamp1.Init.PgaGain = OPAMP_PGA_GAIN_2;
  hopamp1.Init.PowerMode = OPAMP_POWERMODE_NORMALPOWER;
  hopamp1.Init.UserTrimming = OPAMP_TRIMMING_FACTORY;
  if (HAL_OPAMP_Init(&hopamp1) != HAL_OK)
  {
    Error_Handler();
  }

}

void MX_RNG_Init(void)
{

  hrng.Instance = RNG;
  if (HAL_RNG_Init(&hrng) != HAL_OK)
  {
    Error_Handler();
  }

}

void MX_RTC_Init(void)
{

  RTC_TimeTypeDef sTime = {0};
  RTC_DateTypeDef sDate = {0};

  /** Initialize RTC Only
  */
  hrtc.Instance = RTC;
  hrtc.Init.HourFormat = RTC_HOURFORMAT_24;
  hrtc.Init.AsynchPrediv = 127;
  hrtc.Init.SynchPrediv = 255;
  hrtc.Init.OutPut = RTC_OUTPUT_DISABLE;
  hrtc.Init.OutPutRemap = RTC_OUTPUT_REMAP_NONE;
  hrtc.Init.OutPutPolarity = RTC_OUTPUT_POLARITY_HIGH;
  hrtc.Init.OutPutType = RTC_OUTPUT_TYPE_OPENDRAIN;
  if (HAL_RTC_Init(&hrtc) != HAL_OK)
  {
    Error_Handler();
  }

  /* USER CODE BEGIN Check_RTC_BKUP */
  // Do not initialize RTC if the date/time has been set.
  if (!(RTC->ISR & 0x10)) { // Labelled ICSR in the reference manual.

  /* USER CODE END Check_RTC_BKUP */

  /** Initialize RTC and set the Time and Date
  */
  sTime.Hours = 0x0;
  sTime.Minutes = 0x0;
  sTime.Seconds = 0x0;
  sTime.DayLightSaving = RTC_DAYLIGHTSAVING_NONE;
  sTime.StoreOperation = RTC_STOREOPERATION_RESET;
  if (HAL_RTC_SetTime(&hrtc, &sTime, RTC_FORMAT_BCD) != HAL_OK)
  {
    Error_Handler();
  }
  sDate.WeekDay = RTC_WEEKDAY_MONDAY;
  sDate.Month = RTC_MONTH_JANUARY;
  sDate.Date = 0x1;
  sDate.Year = 0x0;

  if (HAL_RTC_SetDate(&hrtc, &sDate, RTC_FORMAT_BCD) != HAL_OK)
  {
    Error_Handler();
  }
  }

}

void MX_TIM1_Init(void)
{

  TIM_ClockConfigTypeDef sClockSourceConfig = {0};
  TIM_MasterConfigTypeDef sMasterConfig = {0};
  TIM_OC_InitTypeDef sConfigOC = {0};
  TIM_BreakDeadTimeConfigTypeDef sBreakDeadTimeConfig = {0};

  htim1.Instance = TIM1;
  htim1.Init.Prescaler = 15;
  htim1.Init.CounterMode = TIM_COUNTERMODE_UP;
  htim1.Init.Period = 9999;
  htim1.Init.ClockDivision = TIM_CLOCKDIVISION_DIV1;
  htim1.Init.RepetitionCounter = 0;
  htim1.Init.AutoReloadPreload = TIM_AUTORELOAD_PRELOAD_DISABLE;
  if (HAL_TIM_Base_Init(&htim1) != HAL_OK)
  {
    Error_Handler();
  }
  sClockSourceConfig.ClockSource = TIM_CLOCKSOURCE_INTERNAL;
  if (HAL_TIM_ConfigClockSource(&htim1, &sClockSourceConfig) != HAL_OK)
  {
    Error_Handler();
  }
  if (HAL_TIM_PWM_Init(&htim1) != HAL_OK)
  {
    Error_Handler();
  }
  sMasterConfig.MasterOutputTrigger = TIM_TRGO_RESET;
  sMasterConfig.MasterOutputTrigger2 = TIM_TRGO2_RESET;
  sMasterConfig.MasterSlaveMode = TIM_MASTERSLAVEMODE_DISABLE;
  if (HAL_TIMEx_MasterConfigSynchronization(&htim1, &sMasterConfig) != HAL_OK)
  {
    Error_Handler();
  }
  sConfigOC.OCMode = TIM_OCMODE_PWM1;
  sConfigOC.Pulse = 0;
  sConfigOC.OCPolarity = TIM_OCPOLARITY_LOW;
  sConfigOC.OCNPolarity = TIM_OCNPOLARITY_HIGH;
  sConfigOC.OCFastMode = TIM_OCFAST_DISABLE;
  sConfigOC.OCIdleState = TIM_OCIDLESTATE_SET;
  sConfigOC.OCNIdleState = TIM_OCNIDLESTATE_RESET;
  if (HAL_TIM_PWM_ConfigChannel(&htim1, &sConfigOC, TIM_CHANNEL_1) != HAL_OK)
  {
    Error_Handler();
  }
  if (HAL_TIM_PWM_ConfigChannel(&htim1, &sConfigOC, TIM_CHANNEL_2) != HAL_OK)
  {
    Error_Handler();
  }
  if (HAL_TIM_PWM_ConfigChannel(&htim1, &sConfigOC, TIM_CHANNEL_3) != HAL_OK)
  {
    Error_Handler();
  }
  sBreakDeadTimeConfig.OffStateRunMode = TIM_OSSR_DISABLE;
  sBreakDeadTimeConfig.OffStateIDLEMode = TIM_OSSI_DISABLE;
  sBreakDeadTimeConfig.LockLevel = TIM_LOCKLEVEL_OFF;
  sBreakDeadTimeConfig.DeadTime = 0;
  sBreakDeadTimeConfig.BreakState = TIM_BREAK_DISABLE;
  sBreakDeadTimeConfig.BreakPolarity = TIM_BREAKPOLARITY_HIGH;
  sBreakDeadTimeConfig.BreakFilter = 0;
  sBreakDeadTimeConfig.Break2State = TIM_BREAK2_DISABLE;
  sBreakDeadTimeConfig.Break2Polarity = TIM_BREAK2POLARITY_HIGH;
  sBreakDeadTimeConfig.Break2Filter = 0;
  sBreakDeadTimeConfig.AutomaticOutput = TIM_AUTOMATICOUTPUT_DISABLE;
  if (HAL_TIMEx_ConfigBreakDeadTime(&htim1, &sBreakDeadTimeConfig) != HAL_OK)
  {
    Error_Handler();
  }
  HAL_TIM_MspPostInit(&htim1);

}

void MX_TIM6_Init(void)
{

  TIM_MasterConfigTypeDef sMasterConfig = {0};

  htim6.Instance = TIM6;
  htim6.Init.Prescaler = 0;
  htim6.Init.CounterMode = TIM_COUNTERMODE_UP;
  htim6.Init.Period = 1817;
  htim6.Init.AutoReloadPreload = TIM_AUTORELOAD_PRELOAD_ENABLE;
  if (HAL_TIM_Base_Init(&htim6) != HAL_OK)
  {
    Error_Handler();
  }
  sMasterConfig.MasterOutputTrigger = TIM_TRGO_UPDATE;
  sMasterConfig.MasterSlaveMode = TIM_MASTERSLAVEMODE_DISABLE;
  if (HAL_TIMEx_MasterConfigSynchronization(&htim6, &sMasterConfig) != HAL_OK)
  {
    Error_Handler();
  }

}

void MX_TIM7_Init(void)
{

  TIM_MasterConfigTypeDef sMasterConfig = {0};

  htim7.Instance = TIM7;
  htim7.Init.Prescaler = 0;
  htim7.Init.CounterMode = TIM_COUNTERMODE_UP;
  htim7.Init.Period = 1817;
  htim7.Init.AutoReloadPreload = TIM_AUTORELOAD_PRELOAD_ENABLE;
  if (HAL_TIM_Base_Init(&htim7) != HAL_OK)
  {
    Error_Handler();
  }
  sMasterConfig.MasterOutputTrigger = TIM_TRGO_UPDATE;
  sMasterConfig.MasterSlaveMode = TIM_MASTERSLAVEMODE_DISABLE;
  if (HAL_TIMEx_MasterConfigSynchronization(&htim7, &sMasterConfig) != HAL_OK)
  {
    Error_Handler();
  }

}

void MX_USART3_UART_Init(void)
{

  huart3.Instance = USART3;
  huart3.Init.BaudRate = 115200;
  huart3.Init.WordLength = UART_WORDLENGTH_8B;
  huart3.Init.StopBits = UART_STOPBITS_1;
  huart3.Init.Parity = UART_PARITY_NONE;
  huart3.Init.Mode = UART_MODE_TX_RX;
  huart3.Init.HwFlowCtl = UART_HWCONTROL_RTS_CTS;
  huart3.Init.OverSampling = UART_OVERSAMPLING_16;
  huart3.Init.OneBitSampling = UART_ONE_BIT_SAMPLE_DISABLE;
  huart3.AdvancedInit.AdvFeatureInit = UART_ADVFEATURE_NO_INIT;
  if (HAL_UART_Init(&huart3) != HAL_OK)
  {
    Error_Handler();
  }

}

static void MX_DMA_Init(void)
{

  /* DMA controller clock enable */
  __HAL_RCC_DMA1_CLK_ENABLE();
  __HAL_RCC_DMA2_CLK_ENABLE();

  /* DMA interrupt init */
  /* DMA1_Channel1_IRQn interrupt configuration */
  HAL_NVIC_SetPriority(DMA1_Channel1_IRQn, 5, 0);
  HAL_NVIC_EnableIRQ(DMA1_Channel1_IRQn);
  /* DMA1_Channel2_IRQn interrupt configuration */
  HAL_NVIC_SetPriority(DMA1_Channel2_IRQn, 5, 0);
  HAL_NVIC_EnableIRQ(DMA1_Channel2_IRQn);
  /* DMA1_Channel3_IRQn interrupt configuration */
  HAL_NVIC_SetPriority(DMA1_Channel3_IRQn, 5, 0);
  HAL_NVIC_EnableIRQ(DMA1_Channel3_IRQn);
  /* DMA1_Channel6_IRQn interrupt configuration */
  HAL_NVIC_SetPriority(DMA1_Channel6_IRQn, 5, 0);
  HAL_NVIC_EnableIRQ(DMA1_Channel6_IRQn);
  /* DMA1_Channel7_IRQn interrupt configuration */
  HAL_NVIC_SetPriority(DMA1_Channel7_IRQn, 5, 0);
  HAL_NVIC_EnableIRQ(DMA1_Channel7_IRQn);
  /* DMA2_Channel4_IRQn interrupt configuration */
  HAL_NVIC_SetPriority(DMA2_Channel4_IRQn, 5, 0);
  HAL_NVIC_EnableIRQ(DMA2_Channel4_IRQn);

}

static void MX_GPIO_Init(void)
{
  GPIO_InitTypeDef GPIO_InitStruct = {0};

  /* GPIO Ports Clock Enable */
  __HAL_RCC_GPIOC_CLK_ENABLE();
  __HAL_RCC_GPIOH_CLK_ENABLE();
  __HAL_RCC_GPIOA_CLK_ENABLE();
  __HAL_RCC_GPIOB_CLK_ENABLE();

  /*Configure GPIO pin Output Level */
  HAL_GPIO_WritePin(BT_WAKE_GPIO_Port, BT_WAKE_Pin, GPIO_PIN_RESET);

  /*Configure GPIO pin Output Level */
  HAL_GPIO_WritePin(GPIOA, BT_SLEEP_Pin|BAT_DIVIDER_Pin, GPIO_PIN_SET);

  /*Configure GPIO pin Output Level */
  HAL_GPIO_WritePin(GPIOB, AUDIO_ATTEN_Pin|VDD_EN_Pin|USB_CE_Pin|BT_CMD_Pin
                          |BT_RESET_Pin, GPIO_PIN_SET);

  /*Configure GPIO pin Output Level */
  HAL_GPIO_WritePin(GPIOB, PTT_B_Pin|PTT_A_Pin, GPIO_PIN_RESET);

  /*Configure GPIO pin : BT_WAKE_Pin */
  GPIO_InitStruct.Pin = BT_WAKE_Pin;
  GPIO_InitStruct.Mode = GPIO_MODE_OUTPUT_OD;
  GPIO_InitStruct.Pull = GPIO_NOPULL;
  GPIO_InitStruct.Speed = GPIO_SPEED_FREQ_LOW;
  HAL_GPIO_Init(BT_WAKE_GPIO_Port, &GPIO_InitStruct);

  /*Configure GPIO pin : USB_POWER_Pin */
  GPIO_InitStruct.Pin = USB_POWER_Pin;
  GPIO_InitStruct.Mode = GPIO_MODE_IT_RISING_FALLING;
  GPIO_InitStruct.Pull = GPIO_PULLDOWN;
  HAL_GPIO_Init(USB_POWER_GPIO_Port, &GPIO_InitStruct);

  /*Configure GPIO pins : SW_POWER_Pin SW_BOOT_Pin */
  GPIO_InitStruct.Pin = SW_POWER_Pin|SW_BOOT_Pin;
  GPIO_InitStruct.Mode = GPIO_MODE_IT_RISING_FALLING;
  GPIO_InitStruct.Pull = GPIO_NOPULL;
  HAL_GPIO_Init(GPIOH, &GPIO_InitStruct);

  /*Configure GPIO pin : BT_SLEEP_Pin */
  GPIO_InitStruct.Pin = BT_SLEEP_Pin;
  GPIO_InitStruct.Mode = GPIO_MODE_OUTPUT_PP;
  GPIO_InitStruct.Pull = GPIO_NOPULL;
  GPIO_InitStruct.Speed = GPIO_SPEED_FREQ_LOW;
  HAL_GPIO_Init(BT_SLEEP_GPIO_Port, &GPIO_InitStruct);

  /*Configure GPIO pins : PA2 PA15 */
  GPIO_InitStruct.Pin = GPIO_PIN_2|GPIO_PIN_15;
  GPIO_InitStruct.Mode = GPIO_MODE_ANALOG;
  GPIO_InitStruct.Pull = GPIO_NOPULL;
  HAL_GPIO_Init(GPIOA, &GPIO_InitStruct);

  /*Configure GPIO pin : BAT_DIVIDER_Pin */
  GPIO_InitStruct.Pin = BAT_DIVIDER_Pin;
  GPIO_InitStruct.Mode = GPIO_MODE_OUTPUT_OD;
  GPIO_InitStruct.Pull = GPIO_NOPULL;
  GPIO_InitStruct.Speed = GPIO_SPEED_FREQ_LOW;
  HAL_GPIO_Init(BAT_DIVIDER_GPIO_Port, &GPIO_InitStruct);

  /*Configure GPIO pins : AUDIO_ATTEN_Pin USB_CE_Pin BT_CMD_Pin BT_RESET_Pin */
  GPIO_InitStruct.Pin = AUDIO_ATTEN_Pin|USB_CE_Pin|BT_CMD_Pin|BT_RESET_Pin;
  GPIO_InitStruct.Mode = GPIO_MODE_OUTPUT_OD;
  GPIO_InitStruct.Pull = GPIO_NOPULL;
  GPIO_InitStruct.Speed = GPIO_SPEED_FREQ_LOW;
  HAL_GPIO_Init(GPIOB, &GPIO_InitStruct);

  /*Configure GPIO pins : VDD_EN_Pin PTT_B_Pin PTT_A_Pin */
  GPIO_InitStruct.Pin = VDD_EN_Pin|PTT_B_Pin|PTT_A_Pin;
  GPIO_InitStruct.Mode = GPIO_MODE_OUTPUT_PP;
  GPIO_InitStruct.Pull = GPIO_NOPULL;
  GPIO_InitStruct.Speed = GPIO_SPEED_FREQ_LOW;
  HAL_GPIO_Init(GPIOB, &GPIO_InitStruct);

  /*Configure GPIO pins : BT_STATE2_Pin BT_STATE1_Pin */
  GPIO_InitStruct.Pin = BT_STATE2_Pin|BT_STATE1_Pin;
  GPIO_InitStruct.Mode = GPIO_MODE_IT_RISING_FALLING;
  GPIO_InitStruct.Pull = GPIO_NOPULL;
  HAL_GPIO_Init(GPIOB, &GPIO_InitStruct);

  /* EXTI interrupt init*/
  HAL_NVIC_SetPriority(EXTI0_IRQn, 5, 0);
  HAL_NVIC_SetPriority(EXTI1_IRQn, 5, 0);
  HAL_NVIC_SetPriority(EXTI3_IRQn, 5, 0);
  HAL_NVIC_SetPriority(EXTI4_IRQn, 5, 0);
  HAL_NVIC_SetPriority(EXTI9_5_IRQn, 5, 0);

}

/* USER CODE BEGIN 4 */

#if 1
_ssize_t _write_r(struct _reent *r, int fd, const void *ptr, size_t len);

_ssize_t _write_r(struct _reent *r, int fd, const void *ptr, size_t len)
{
  UNUSED(r);
  UNUSED(fd);
#ifdef KISS_LOGGING
    for (size_t i = 0; i != len; ++i)
      ITM_SendChar(((char*) ptr)[i]);
#endif
  return len;
}

int _write(int file, char *ptr, int len);

int _write(int file, char *ptr, int len) {
    UNUSED(file);
#ifdef KISS_LOGGING
    for (int i = 0; i != len; ++i)
      ITM_SendChar(ptr[i]);
#endif
    return len;

}
#endif

/**
 * @page Clock Configuration
 *
 * The clock configurations are used to reduce power consumption to the
 * minimum required by the system components and the modem selected.
 *
 * It is required that no modem is active (audio input is IDLE) when switching
 * clocks.
 *
 * Note that HSI48, which consumes quite a bit of power, is never enabled in
 * any of these clock modes.
 *
 * 16MHz Clock
 *
 * The 16MHz clock is only used at startup. The clock tree is set as close
 * as possible to the other clock modes. This is only used when initializing
 * the peripherals. MSI set to 48MHz in PLL mode.
 *
 * LSE, LSI, MSI and HSI are enabled.
 *
 * LSE is used for RTC and MSI PLL.
 * LSI is used for IWDG.
 * HSI is used for SYSCLK, UART, and I2C.
 * MSI is used for RNG and USB.
 *
 * 2MHz Clock
 *
 * When disconnected and on battery power, the clock is set to 2MHz. In this
 * mode, almost all peripheral clocks are gated. It is required that both the
 * USB and RNG clocks are gated before switching to the 2MHz clock as they are
 * driven by the MSI directly; both must driven by a 48MHz clock.
 *
 * The ADC is used solely for monitoring the power domain via a VREFINT
 * watchdog. The ADC is clocked from SYSCLK in this mode.
 *
 * LSE, LSI, MSI, HSI are enabled.
 *
 * LSE is used for RTC and MSI PLL.
 * LSI is used for IWDG.
 * HSI is used for UART and I2C.
 * MSI is used for SYSCLK (RNG and USB gated).
 * PLL is disabled and unused.
 *
 * LCSO is only enabled for DEBUG builds.
 *
 * In this mode, voltage scaling is reduced to the lowest possible. The system
 * is in low power run mode.
 *
 * 48MHz Clock
 *
 * When powered by USB, or when needed by a modem, the 48MHz clock is used.
 * In this mode, most peripherals are disabled in disconnected mode, and
 * enabled in connected mode.
 *
 * The MSI clock is running at 48MHz in PLL mode to get the most accurate
 * clock possible (48.005Mhz, 32768Hz * 1465) in a system without an HSE.
 *
 * The ADC is driven by PLLSAIR at 80MHz so that it can be used in injected
 * watchdog mode. At 80Mhz the ADC can do 48000 samples per second of two
 * channels at 24.5 cycles and 16x oversampling.
 *
 * LSE, LSI, MSI, HSI are enabled.
 *
 * LSE is used for RTC and MSI PLL.
 * LSI is used for IWDG.
 * HSI is used for UART and I2C.
 * MSI is used for SYSCLK, RNG and USB.
 * PLLSAIR is used for ADC.
 *
 * 72MHz Clock
 *
 * When needed by a modem, the 72MHz clock is used. Currently this is only
 * used by the 9600 baud GFSK modem. In this mode, most peripherals are
 * disabled in disconnected mode, and enabled in connected mode. This mode
 * may be used when plugged in to USB and disconnected.
 *
 * The MSI clock is running at 48MHz in PLL mode to get the most accurate
 * clock possible (48.005Mhz, 32768Hz * 1465) in a system without an HSE.
 *
 * The ADC is driven by PLLSAIR at 80MHz so that it can be used in injected
 * watchdog mode. At 80Mhz the ADC can do 96000 samples per second of two
 * channels at 12.5 cycles and 16x oversampling.
 *
 * LSE, LSI, MSI, HSI are enabled.
 *
 * LSE is used for RTC and MSI PLL.
 * LSI is used for IWDG.
 * HSI is used for UART and I2C.
 * MSI is used for RNG and USB.
 * PLL/R is used for SYSCLK.
 * PLLSAIR is used for ADC.
 */

void SysClock2()
{
    RCC_OscInitTypeDef RCC_OscInitStruct = {};
    RCC_ClkInitTypeDef RCC_ClkInitStruct = {};
    RCC_PeriphCLKInitTypeDef PeriphClkInit = {};
    HAL_StatusTypeDef status = HAL_OK;

    if (HAL_RCC_GetHCLKFreq() == 2000000) return;

    INFO("Setting 2MHz SysClock.");

    vTaskSuspendAll();

    // Disable low power run mode.
    HAL_RCCEx_DisableMSIPLLMode();
    status = HAL_PWREx_DisableLowPowerRunMode();
    if (status != HAL_OK) {
        _Error_Handler2(__FILE_NAME__, __LINE__, status);
    }

    RCC_ClkInitStruct.ClockType = RCC_CLOCKTYPE_SYSCLK;
    RCC_ClkInitStruct.SYSCLKSource = RCC_SYSCLKSOURCE_HSI;

    status = HAL_RCC_ClockConfig(&RCC_ClkInitStruct, FLASH_LATENCY_0);
    if (status != HAL_OK)
    {
      _Error_Handler2(__FILE_NAME__, __LINE__, status);
    }

    TPI->ACPR = 7;  // 16MHz clock, 2MHz SWO
    __HAL_TIM_SET_PRESCALER(&LED_PWM_TIMER_HANDLE, 15);

    /**Configure the Systick interrupt time
    */
    HAL_SYSTICK_Config(HAL_RCC_GetHCLKFreq()/1000);

    // PLLSAI cannot be used when disabling or modifying the PLL.
    PeriphClkInit.PeriphClockSelection = RCC_PERIPHCLK_ADC;
    PeriphClkInit.AdcClockSelection = RCC_ADCCLKSOURCE_SYSCLK;

    status = HAL_RCCEx_PeriphCLKConfig(&PeriphClkInit);
    if (status != HAL_OK)
    {
      _Error_Handler2(__FILE_NAME__, __LINE__, status);
    }

    RCC_OscInitStruct.OscillatorType = RCC_OSCILLATORTYPE_MSI;
    RCC_OscInitStruct.MSIState = RCC_MSI_ON;
    RCC_OscInitStruct.MSICalibrationValue = RCC_MSICALIBRATION_DEFAULT;
    RCC_OscInitStruct.MSIClockRange = RCC_MSIRANGE_5; // 2MHz
    RCC_OscInitStruct.PLL.PLLState = RCC_PLL_OFF;
    RCC_OscInitStruct.PLL.PLLSource = RCC_PLLSOURCE_HSI;
    if (HAL_RCC_OscConfig(&RCC_OscInitStruct) != HAL_OK)
    {
      _Error_Handler(__FILE_NAME__, __LINE__);
    }

    RCC_ClkInitStruct.ClockType = RCC_CLOCKTYPE_SYSCLK;
    RCC_ClkInitStruct.SYSCLKSource = RCC_SYSCLKSOURCE_MSI;

    status = HAL_RCC_ClockConfig(&RCC_ClkInitStruct, FLASH_LATENCY_0);
    if (status != HAL_OK)
    {
      _Error_Handler2(__FILE_NAME__, __LINE__, status);
    }

    TPI->ACPR = 0;  // 2MHz clock, 2MHz SWO
    __HAL_TIM_SET_PRESCALER(&LED_PWM_TIMER_HANDLE, 1);
    __HAL_TIM_SET_PRESCALER(&htim6, 7);
    __HAL_TIM_SET_AUTORELOAD(&htim6, 249);

    // Reduce voltage scaling and set low power run mode.
    status = HAL_PWREx_ControlVoltageScaling(PWR_REGULATOR_VOLTAGE_SCALE2);
    if (status != HAL_OK) {
        _Error_Handler2(__FILE_NAME__, __LINE__, status);
    }
    HAL_PWREx_EnableLowPowerRunMode();

    HAL_RCCEx_EnableMSIPLLMode();

    /**Configure the Systick interrupt time
    */
    HAL_SYSTICK_Config(HAL_RCC_GetHCLKFreq()/1000);

#ifdef KISS_LOGGING
    HAL_RCCEx_EnableLSCO(RCC_LSCOSOURCE_LSE);
#else
    HAL_RCCEx_DisableLSCO();
#endif

    INFO("CPU core clock: %luHz", SystemCoreClock);

    HAL_Delay(10);

    xTaskResumeAll();
}

void SysClock48()
{
    RCC_OscInitTypeDef RCC_OscInitStruct = {};
    RCC_ClkInitTypeDef RCC_ClkInitStruct = {};
    RCC_PeriphCLKInitTypeDef PeriphClkInit = {};
    HAL_StatusTypeDef status;

    if (HAL_RCC_GetHCLKFreq() == 48000000) return;

    INFO("Setting 48MHz SysClock.");

    vTaskSuspendAll();

    // Disable low power run mode and set the voltage scaling to maximum.
    HAL_RCCEx_DisableMSIPLLMode();
    status = HAL_PWREx_DisableLowPowerRunMode();
    if (status != HAL_OK) {
        _Error_Handler2(__FILE_NAME__, __LINE__, status);
    }
    status = HAL_PWREx_ControlVoltageScaling(PWR_REGULATOR_VOLTAGE_SCALE1);
    if (status != HAL_OK) {
        _Error_Handler2(__FILE_NAME__, __LINE__, status);
    }

    RCC_ClkInitStruct.ClockType = RCC_CLOCKTYPE_SYSCLK;
    RCC_ClkInitStruct.SYSCLKSource = RCC_SYSCLKSOURCE_HSI;

    status = HAL_RCC_ClockConfig(&RCC_ClkInitStruct, FLASH_LATENCY_0);
    if (status != HAL_OK)
    {
      _Error_Handler2(__FILE_NAME__, __LINE__, status);
    }

    TPI->ACPR = 7;  // 16MHz clock, 2MHz SWO
    __HAL_TIM_SET_PRESCALER(&LED_PWM_TIMER_HANDLE, 15);

    /**Configure the Systick interrupt time
    */
    HAL_SYSTICK_Config(HAL_RCC_GetHCLKFreq()/1000);

    // PLLSAI cannot be used when disabling or modifying the PLL.
    PeriphClkInit.PeriphClockSelection = RCC_PERIPHCLK_ADC;
    PeriphClkInit.AdcClockSelection = RCC_ADCCLKSOURCE_SYSCLK;
    if (HAL_RCCEx_PeriphCLKConfig(&PeriphClkInit) != HAL_OK)
    {
      _Error_Handler(__FILE_NAME__, __LINE__);
    }

    RCC_OscInitStruct.OscillatorType = RCC_OSCILLATORTYPE_MSI;
    RCC_OscInitStruct.MSIState = RCC_MSI_ON;
    RCC_OscInitStruct.MSICalibrationValue = RCC_MSICALIBRATION_DEFAULT;
    RCC_OscInitStruct.MSIClockRange = RCC_MSIRANGE_11;
    RCC_OscInitStruct.PLL.PLLState = RCC_PLL_ON;
    RCC_OscInitStruct.PLL.PLLSource = RCC_PLLSOURCE_MSI;
    RCC_OscInitStruct.PLL.PLLM = 6;
    RCC_OscInitStruct.PLL.PLLN = 12;
    RCC_OscInitStruct.PLL.PLLP = RCC_PLLP_DIV2;
    RCC_OscInitStruct.PLL.PLLQ = RCC_PLLQ_DIV2;
    RCC_OscInitStruct.PLL.PLLR = RCC_PLLR_DIV2;
    if (HAL_RCC_OscConfig(&RCC_OscInitStruct) != HAL_OK)
    {
      _Error_Handler(__FILE_NAME__, __LINE__);
    }

    RCC_ClkInitStruct.ClockType = RCC_CLOCKTYPE_SYSCLK;
    RCC_ClkInitStruct.SYSCLKSource = RCC_SYSCLKSOURCE_MSI;

    // STM32L433 at 48MHz requires at least 2 wait states.
    status = HAL_RCC_ClockConfig(&RCC_ClkInitStruct, FLASH_LATENCY_2);
    if (status != HAL_OK)
    {
      _Error_Handler2(__FILE_NAME__, __LINE__, status);
    }

    TPI->ACPR = 23;  // 48MHz clock, 2MHz SWO
    __HAL_TIM_SET_PRESCALER(&LED_PWM_TIMER_HANDLE, 47);
    __HAL_TIM_SET_PRESCALER(&htim6, 0);

    PeriphClkInit.PeriphClockSelection = RCC_PERIPHCLK_ADC;
    PeriphClkInit.AdcClockSelection = RCC_ADCCLKSOURCE_PLLSAI1;
    PeriphClkInit.PLLSAI1.PLLSAI1Source = RCC_PLLSOURCE_MSI;
    PeriphClkInit.PLLSAI1.PLLSAI1M = 6;
    PeriphClkInit.PLLSAI1.PLLSAI1N = 20;
    PeriphClkInit.PLLSAI1.PLLSAI1P = 2;
    PeriphClkInit.PLLSAI1.PLLSAI1Q = 2;
    PeriphClkInit.PLLSAI1.PLLSAI1R = 2;
    PeriphClkInit.PLLSAI1.PLLSAI1ClockOut = RCC_PLLSAI1_ADC1CLK;
    if (HAL_RCCEx_PeriphCLKConfig(&PeriphClkInit) != HAL_OK)
    {
      _Error_Handler(__FILE_NAME__, __LINE__);
    }

    HAL_RCCEx_EnableMSIPLLMode();

    /**Configure the Systick interrupt time
    */
    HAL_SYSTICK_Config(HAL_RCC_GetHCLKFreq()/1000);

#ifdef KISS_LOGGING
    HAL_RCCEx_EnableLSCO(RCC_LSCOSOURCE_LSE);
#else
    HAL_RCCEx_DisableLSCO();
#endif

    INFO("CPU core clock: %luHz", SystemCoreClock);

    HAL_Delay(10);

    xTaskResumeAll();
}

void SysClock72()
{
    RCC_OscInitTypeDef RCC_OscInitStruct = {};
    RCC_ClkInitTypeDef RCC_ClkInitStruct = {};
    RCC_PeriphCLKInitTypeDef PeriphClkInit = {};
    HAL_StatusTypeDef status;

    if (HAL_RCC_GetHCLKFreq() == 72000000) return;

    INFO("Setting 72MHz SysClock.");

    vTaskSuspendAll();

    // Disable low power run mode and set the voltage scaling to maximum.
    HAL_RCCEx_DisableMSIPLLMode();
    status = HAL_PWREx_DisableLowPowerRunMode();
    if (status != HAL_OK) {
        _Error_Handler2(__FILE_NAME__, __LINE__, status);
    }
    status = HAL_PWREx_ControlVoltageScaling(PWR_REGULATOR_VOLTAGE_SCALE1);
    if (status != HAL_OK) {
        _Error_Handler2(__FILE_NAME__, __LINE__, status);
    }

    RCC_ClkInitStruct.ClockType = RCC_CLOCKTYPE_SYSCLK;
    RCC_ClkInitStruct.SYSCLKSource = RCC_SYSCLKSOURCE_HSI;

    if (HAL_RCC_ClockConfig(&RCC_ClkInitStruct, FLASH_LATENCY_0) != HAL_OK)
    {
      _Error_Handler(__FILE_NAME__, __LINE__);
    }

    TPI->ACPR = 7;  // 16MHz clock, 2MHz SWO
    __HAL_TIM_SET_PRESCALER(&LED_PWM_TIMER_HANDLE, 15);

    /**Configure the Systick interrupt time
    */
    HAL_SYSTICK_Config(HAL_RCC_GetHCLKFreq()/1000);

    // PLLSAI cannot be used when disabling or modifying the PLL.
    PeriphClkInit.PeriphClockSelection = RCC_PERIPHCLK_ADC;
    PeriphClkInit.AdcClockSelection = RCC_ADCCLKSOURCE_SYSCLK;
    if (HAL_RCCEx_PeriphCLKConfig(&PeriphClkInit) != HAL_OK)
    {
      _Error_Handler(__FILE_NAME__, __LINE__);
    }

    RCC_OscInitStruct.OscillatorType = RCC_OSCILLATORTYPE_MSI;
    RCC_OscInitStruct.MSIState = RCC_MSI_ON;
    RCC_OscInitStruct.MSICalibrationValue = RCC_MSICALIBRATION_DEFAULT;
    RCC_OscInitStruct.MSIClockRange = RCC_MSIRANGE_11;
    RCC_OscInitStruct.PLL.PLLState = RCC_PLL_ON;
    RCC_OscInitStruct.PLL.PLLSource = RCC_PLLSOURCE_MSI;
    RCC_OscInitStruct.PLL.PLLM = 6;
    RCC_OscInitStruct.PLL.PLLN = 18;
    RCC_OscInitStruct.PLL.PLLP = RCC_PLLP_DIV7;
    RCC_OscInitStruct.PLL.PLLQ = RCC_PLLQ_DIV2;
    RCC_OscInitStruct.PLL.PLLR = RCC_PLLR_DIV2;
    if (HAL_RCC_OscConfig(&RCC_OscInitStruct) != HAL_OK)
    {
      _Error_Handler(__FILE_NAME__, __LINE__);
    }

    RCC_ClkInitStruct.ClockType = RCC_CLOCKTYPE_SYSCLK;
    RCC_ClkInitStruct.SYSCLKSource = RCC_SYSCLKSOURCE_PLLCLK;

    // STM32L433 at 72MHz requires at least 4 wait states.
    status = HAL_RCC_ClockConfig(&RCC_ClkInitStruct, FLASH_LATENCY_4);
    if (status != HAL_OK)
    {
      _Error_Handler2(__FILE_NAME__, __LINE__, status);
    }

    TPI->ACPR = 35;  // 72MHz clock, 2MHz SWO
    __HAL_TIM_SET_PRESCALER(&LED_PWM_TIMER_HANDLE, 71);
    __HAL_TIM_SET_PRESCALER(&htim6, 0);

    PeriphClkInit.PeriphClockSelection = RCC_PERIPHCLK_ADC;
    PeriphClkInit.AdcClockSelection = RCC_ADCCLKSOURCE_PLLSAI1;
    PeriphClkInit.PLLSAI1.PLLSAI1Source = RCC_PLLSOURCE_MSI;
    PeriphClkInit.PLLSAI1.PLLSAI1M = 6;
    PeriphClkInit.PLLSAI1.PLLSAI1N = 20;
    PeriphClkInit.PLLSAI1.PLLSAI1P = 2;
    PeriphClkInit.PLLSAI1.PLLSAI1Q = 2;
    PeriphClkInit.PLLSAI1.PLLSAI1R = 2;
    PeriphClkInit.PLLSAI1.PLLSAI1ClockOut = RCC_PLLSAI1_ADC1CLK;
    if (HAL_RCCEx_PeriphCLKConfig(&PeriphClkInit) != HAL_OK)
    {
      _Error_Handler(__FILE_NAME__, __LINE__);
    }

    HAL_RCCEx_EnableMSIPLLMode();

    /**Configure the Systick interrupt time
    */
    HAL_SYSTICK_Config(HAL_RCC_GetHCLKFreq()/1000);

#ifdef KISS_LOGGING
    HAL_RCCEx_EnableLSCO(RCC_LSCOSOURCE_LSE);
#else
    HAL_RCCEx_DisableLSCO();
#endif

    INFO("CPU core clock: %luHz", SystemCoreClock);

    HAL_Delay(10);

    xTaskResumeAll();
}

/**
  * @brief  This function is executed in case of error occurrence.
  * @param  file: The file name as string.
  * @param  line: The line in file as a number.
  * @retval None
  */
void _Error_Handler(char *file, int line)
{
#ifdef KISS_LOGGING
  printf("Error handler called from file %s on line %d\r\n", file, line);
#endif
  snprintf(error_message, sizeof(error_message), "Error: %s:%d", file, line);
  error_message[sizeof(error_message) - 1] = 0;

  go_back_to_sleep = 0;

  vTaskSuspendAll(); // Will eventually cause IWDG reset.

  error_code(MORSE_1, MORSE_1);
}

void _Error_Handler2(char *file, int line, HAL_StatusTypeDef status)
{
#ifdef KISS_LOGGING
  printf("Error handler called from file %s on line %d, status = %d\r\n", file, line, status);
#endif
  snprintf(error_message, sizeof(error_message), "Error: %s:%d, status = %d", file, line, status);
  error_message[sizeof(error_message) - 1] = 0;

  go_back_to_sleep = 0;

  vTaskSuspendAll(); // Will eventually cause IWDG reset.

  error_code(MORSE_1, MORSE_1);
}
volatile uint32_t delay_count = 0;

void delay(uint32_t ms) {
  delay_count = (SystemCoreClock >> 13) * ms;
  for (uint32_t i = 0; i != delay_count; ++i) asm volatile("nop");
}

void dit()
{
  HAL_GPIO_WritePin(LED_TX_GPIO_Port, LED_TX_Pin, GPIO_PIN_RESET);
  delay(100);
  HAL_GPIO_WritePin(LED_TX_GPIO_Port, LED_TX_Pin, GPIO_PIN_SET);
  delay(100);
}

void dah()
{
  HAL_GPIO_WritePin(LED_TX_GPIO_Port, LED_TX_Pin, GPIO_PIN_RESET);
  delay(300);
  HAL_GPIO_WritePin(LED_TX_GPIO_Port, LED_TX_Pin, GPIO_PIN_SET);
  delay(100);
}

void brk1()
{
  delay(300);
}

void brk2()
{
  delay(700);
}

/**
 * Output a two-digit error code in Morse. This outputs an error code non-stop
 * in Morse code to the TX LED (red). Once this code is hit, the TNC will need
 * to be reset.
 *
 * The code is passed as a 5-bit value, with 1 = dit, 0 = dah.
 *
 * For example:
 *  0 = 00000 / 0x00
 *  1 = 10000 / 0x10
 *  2 = 11000 / 0x18
 *  3 = 11100 / 0x1C
 *  4 = 11110 / 0x1E
 *  5 = 11111 / 0x1F
 *  6 = 01111 / 0x0F
 *  7 = 00111 / 0x07
 *  8 = 00011 / 0x03
 *  9 = 00001 / 0x01
 */
void error_code(int8_t a, int8_t b)
{
  GPIO_InitTypeDef GPIO_InitStruct = {0};

  HAL_TIM_PWM_DeInit(&LED_PWM_TIMER_HANDLE);  // Disable PWM.

  // Re-initialize LED GPIO.
  GPIO_InitStruct.Pin = LED_BT_Pin|LED_RX_Pin|LED_TX_Pin;
  GPIO_InitStruct.Mode = GPIO_MODE_OUTPUT_OD;
  GPIO_InitStruct.Pull = GPIO_NOPULL;
  GPIO_InitStruct.Speed = GPIO_SPEED_FREQ_LOW;
  HAL_GPIO_Init(GPIOC, &GPIO_InitStruct);

  HAL_GPIO_WritePin(LED_BT_GPIO_Port, LED_BT_Pin, GPIO_PIN_SET);
  HAL_GPIO_WritePin(LED_RX_GPIO_Port, LED_RX_Pin, GPIO_PIN_SET);
  HAL_GPIO_WritePin(LED_TX_GPIO_Port, LED_TX_Pin, GPIO_PIN_SET);

  a &= 0x1F;
  b &= 0x1F;
  for (uint8_t j = 0; j != 3; ++j)
  {
    int8_t aa = a;
    for (int i = 0; i != 5; ++i)
    {
      if (aa & 0x10) dit(); else dah();
      aa <<= 1;
    }
    brk1();
    int8_t bb = b;
    for (int i = 0; i != 5; ++i)
    {
      if (bb & 0x10) dit(); else dah();
      bb <<= 1;
    }
    brk2();
  }
  NVIC_SystemReset();
}

void __assert_fail(const char *expr, const char *file, unsigned int line, const char *function)
{
  snprintf(error_message, sizeof(error_message), "Assertion %s failed in %s at %s:%u", expr, function, file, line);
  ERROR("Assertion %s failed in %s at %s:%u", expr, function, file, line);
  error_code(0,0);
}

/* USER CODE END 4 */

__weak void startIOEventTask(void const * argument)
{
  /* USER CODE BEGIN 5 */
  /* Infinite loop */
  for(;;)
  {
    osDelay(osWaitForever);
  }
  /* USER CODE END 5 */
}

/* shutdown function */
void shutdown(void const * argument)
{
  /* USER CODE BEGIN shutdown */
  UNUSED(argument);
  osMessagePut(ioEventQueueHandle, CMD_SHUTDOWN, 0);
  /* USER CODE END shutdown */
}

/* powerOffTimerCallback function */
void powerOffTimerCallback(void const * argument)
{
  /* USER CODE BEGIN powerOffTimerCallback */

  UNUSED(argument);
  INFO("shutdown timer triggered");
  osMessagePut(ioEventQueueHandle, CMD_SHUTDOWN, 0);

  /* USER CODE END powerOffTimerCallback */
}

void HAL_TIM_PeriodElapsedCallback(TIM_HandleTypeDef *htim)
{
  if (htim->Instance == TIM2) {
    HAL_IncTick();
  }
  /* USER CODE BEGIN Callback 1 */
  if (htim->Instance == TIM1) {
      LED_TIMER_PeriodElapsedCallback();
  }

  /* USER CODE END Callback 1 */
}

void Error_Handler(void)
{
  /* USER CODE BEGIN Error_Handler_Debug */
  /* User can add his own implementation to report the HAL error return state */
  go_back_to_sleep = 0;
  NVIC_SystemReset();
  /* USER CODE END Error_Handler_Debug */
}

#ifdef  USE_FULL_ASSERT
/**
  * @brief  Reports the name of the source file and the source line number
  *         where the assert_param error has occurred.
  * @param  file: pointer to the source file name
  * @param  line: assert_param error line source number
  * @retval None
  */
void assert_failed(uint8_t *file, uint32_t line)
{
  /* USER CODE BEGIN 6 */
  /* User can add his own implementation to report the file name and line number,
     tex: printf("Wrong parameters value: file %s on line %d\r\n", file, line) */
    snprintf(error_message, sizeof(error_message), "Wrong parameters value: file %s on line %lu", file, line);
    ERROR("Wrong parameters value: file %s on line %lu", file, line);
    error_code(0,0);
  /* USER CODE END 6 */
}
#endif /* USE_FULL_ASSERT */

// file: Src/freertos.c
/* USER CODE BEGIN Header */
/**
  ******************************************************************************
  * File Name          : freertos.c
  * Description        : Code for freertos applications
  ******************************************************************************
  * This notice applies to any and all portions of this file
  * that are not between comment pairs USER CODE BEGIN and
  * USER CODE END. Other portions of this file, whether
  * inserted by the user or by software development tools
  * are owned by their respective copyright owners.
  *
  * Copyright (c) 2018 STMicroelectronics International N.V.
  * All rights reserved.
  *
  * Redistribution and use in source and binary forms, with or without
  * modification, are permitted, provided that the following conditions are met:
  *
  * 1. Redistribution of source code must retain the above copyright notice,
  *    this list of conditions and the following disclaimer.
  * 2. Redistributions in binary form must reproduce the above copyright notice,
  *    this list of conditions and the following disclaimer in the documentation
  *    and/or other materials provided with the distribution.
  * 3. Neither the name of STMicroelectronics nor the names of other
  *    contributors to this software may be used to endorse or promote products
  *    derived from this software without specific written permission.
  * 4. This software, including modifications and/or derivative works of this
  *    software, must execute solely and exclusively on microcontroller or
  *    microprocessor devices manufactured by or for STMicroelectronics.
  * 5. Redistribution and use of this software other than as permitted under
  *    this license is void and will automatically terminate your rights under
  *    this license.
  *
  * THIS SOFTWARE IS PROVIDED BY STMICROELECTRONICS AND CONTRIBUTORS "AS IS"
  * AND ANY EXPRESS, IMPLIED OR STATUTORY WARRANTIES, INCLUDING, BUT NOT
  * LIMITED TO, THE IMPLIED WARRANTIES OF MERCHANTABILITY, FITNESS FOR A
  * PARTICULAR PURPOSE AND NON-INFRINGEMENT OF THIRD PARTY INTELLECTUAL PROPERTY
  * RIGHTS ARE DISCLAIMED TO THE FULLEST EXTENT PERMITTED BY LAW. IN NO EVENT
  * SHALL STMICROELECTRONICS OR CONTRIBUTORS BE LIABLE FOR ANY DIRECT, INDIRECT,
  * INCIDENTAL, SPECIAL, EXEMPLARY, OR CONSEQUENTIAL DAMAGES (INCLUDING, BUT NOT
  * LIMITED TO, PROCUREMENT OF SUBSTITUTE GOODS OR SERVICES; LOSS OF USE, DATA,
  * OR PROFITS; OR BUSINESS INTERRUPTION) HOWEVER CAUSED AND ON ANY THEORY OF
  * LIABILITY, WHETHER IN CONTRACT, STRICT LIABILITY, OR TORT (INCLUDING
  * NEGLIGENCE OR OTHERWISE) ARISING IN ANY WAY OUT OF THE USE OF THIS SOFTWARE,
  * EVEN IF ADVISED OF THE POSSIBILITY OF SUCH DAMAGE.
  *
  ******************************************************************************
  */
/* USER CODE END Header */

#include "FreeRTOS.h"
#include "task.h"
#include "main.h"

/* GetIdleTaskMemory prototype (linked to static allocation support) */
void vApplicationGetIdleTaskMemory( StaticTask_t **ppxIdleTaskTCBBuffer, StackType_t **ppxIdleTaskStackBuffer, uint32_t *pulIdleTaskStackSize );

/* GetTimerTaskMemory prototype (linked to static allocation support) */
void vApplicationGetTimerTaskMemory( StaticTask_t **ppxTimerTaskTCBBuffer, StackType_t **ppxTimerTaskStackBuffer, uint32_t *pulTimerTaskStackSize );

/* Hook prototypes */
void vApplicationStackOverflowHook(TaskHandle_t xTask, signed char *pcTaskName);
void vApplicationMallocFailedHook(void);

/* USER CODE BEGIN 4 */
__weak void vApplicationStackOverflowHook(TaskHandle_t xTask, signed char *pcTaskName)
{
   /* Run time stack overflow checking is performed if
   configCHECK_FOR_STACK_OVERFLOW is defined to 1 or 2. This hook function is
   called if a stack overflow is detected. */
}
/* USER CODE END 4 */

/* USER CODE BEGIN 5 */
__weak void vApplicationMallocFailedHook(void)
{
   /* vApplicationMallocFailedHook() will only be called if
   configUSE_MALLOC_FAILED_HOOK is set to 1 in FreeRTOSConfig.h. It is a hook
   function that will get called if a call to pvPortMalloc() fails.
   pvPortMalloc() is called internally by the kernel whenever a task, queue,
   timer or semaphore is created. It is also called by various parts of the
   demo application. If heap_1.c or heap_2.c are used, then the size of the
   heap available to pvPortMalloc() is defined by configTOTAL_HEAP_SIZE in
   FreeRTOSConfig.h, and the xPortGetFreeHeapSize() API function can be used
   to query the size of free heap space that remains (although it does not
   provide information on how the remaining heap might be fragmented). */
}
/* USER CODE END 5 */

/* USER CODE BEGIN GET_IDLE_TASK_MEMORY */
static StaticTask_t xIdleTaskTCBBuffer;
static StackType_t xIdleStack[configMINIMAL_STACK_SIZE];

void vApplicationGetIdleTaskMemory( StaticTask_t **ppxIdleTaskTCBBuffer, StackType_t **ppxIdleTaskStackBuffer, uint32_t *pulIdleTaskStackSize )
{
  *ppxIdleTaskTCBBuffer = &xIdleTaskTCBBuffer;
  *ppxIdleTaskStackBuffer = &xIdleStack[0];
  *pulIdleTaskStackSize = configMINIMAL_STACK_SIZE;
  /* place for user code */
}
/* USER CODE END GET_IDLE_TASK_MEMORY */

/* USER CODE BEGIN GET_TIMER_TASK_MEMORY */
static StaticTask_t xTimerTaskTCBBuffer;
static StackType_t xTimerStack[configTIMER_TASK_STACK_DEPTH];

void vApplicationGetTimerTaskMemory( StaticTask_t **ppxTimerTaskTCBBuffer, StackType_t **ppxTimerTaskStackBuffer, uint32_t *pulTimerTaskStackSize )
{
  *ppxTimerTaskTCBBuffer = &xTimerTaskTCBBuffer;
  *ppxTimerTaskStackBuffer = &xTimerStack[0];
  *pulTimerTaskStackSize = configTIMER_TASK_STACK_DEPTH;
  /* place for user code */
}
/* USER CODE END GET_TIMER_TASK_MEMORY */
